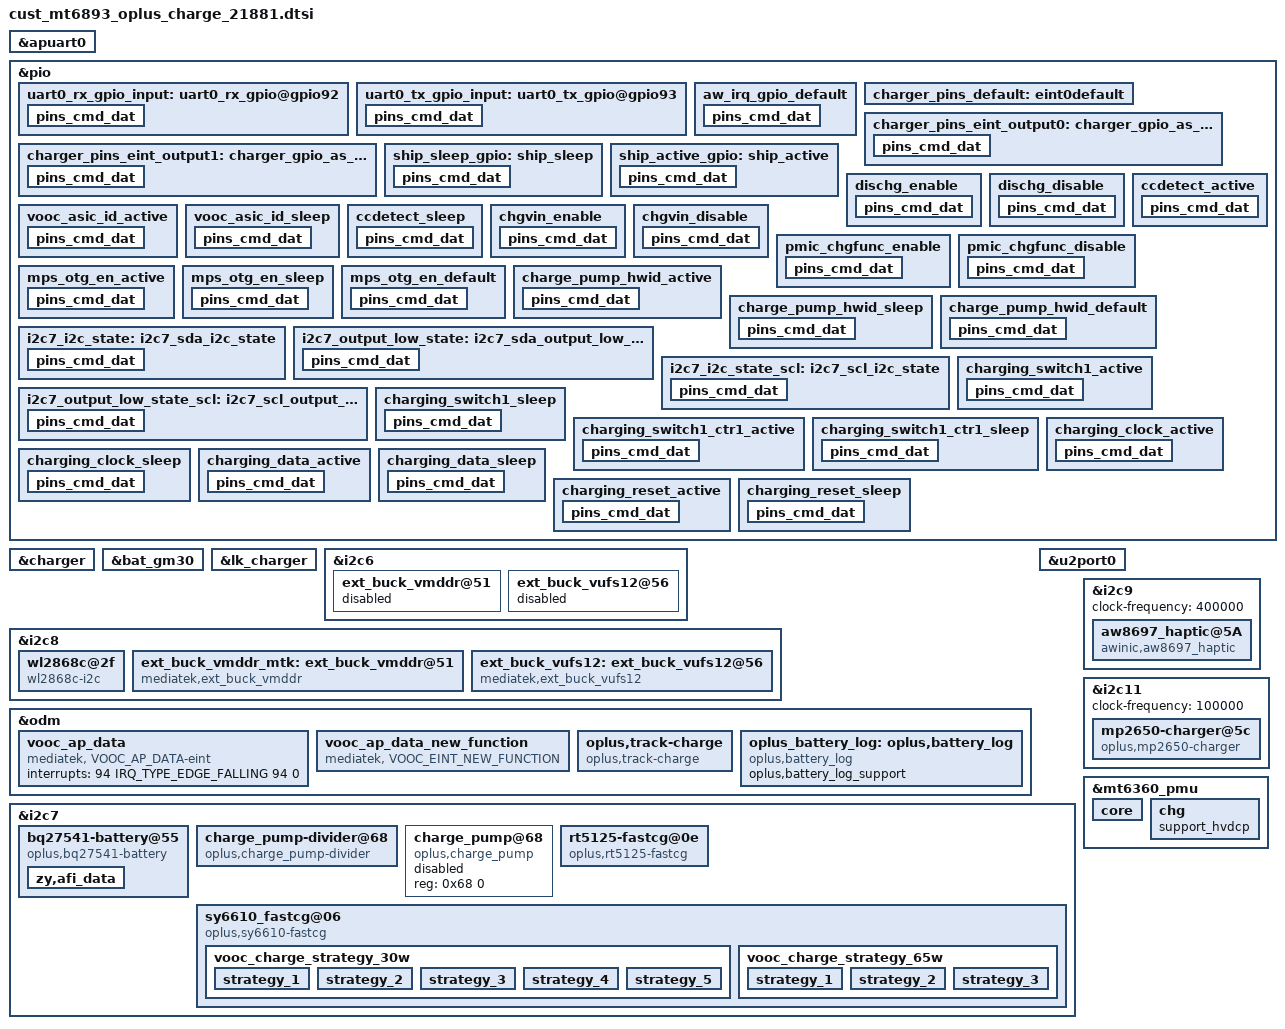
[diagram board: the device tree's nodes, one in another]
// SPDX-License-Identifier: GPL-2.0-only
/*
* Copyright (C) 2021-2020 Oplus. All rights reserved.
*/

/* charge start */
&apuart0 {
	pinctrl-names = "uart0_rx_gpio", "uart0_tx_gpio";
	pinctrl-0 = <&uart0_rx_gpio_input>;
	pinctrl-1 = <&uart0_tx_gpio_input>;
	status = "okay";
};

&pio {
	uart0_rx_gpio_input:uart0_rx_gpio@gpio92 {
		pins_cmd_dat {
			pinmux = <PINMUX_GPIO92__FUNC_GPIO92>;
			input-enable;
			slew-rate = <0>;
			bias-disable;
		};
	};

	uart0_tx_gpio_input:uart0_tx_gpio@gpio93 {
		pins_cmd_dat {
			pinmux = <PINMUX_GPIO93__FUNC_GPIO93>;
			input-enable;
			slew-rate = <0>;
			bias-disable;
		};
	};
};
&charger {
	io-channels =  <&auxadc 4>,
		<&auxadc 5>;
	io-channel-names = "auxadc4-usb_temp_v_l",
	"auxadc5-usb_temp_v_r";

	pinctrl-names = "default", "charger_gpio_as_output_low", "charger_gpio_as_output_high", "ship_sleep", "ship_active",
		"dischg_enable", "dischg_disable", "chgvin_enable", "chgvin_disable", "pmic_chgfunc_enable", "pmic_chgfunc_disable",
		"ccdetect_active","ccdetect_sleep";
	pinctrl-0 = <&charger_pins_default>;
	pinctrl-1 = <&charger_pins_eint_output0>;	//USB_ON -> USB_SWITCH:(UART && USB)
	pinctrl-2 = <&charger_pins_eint_output1>;
	pinctrl-3 = <&ship_sleep_gpio>;				//ship_mode
	pinctrl-4 = <&ship_active_gpio>;
	pinctrl-5 = <&dischg_enable>;				//usb_hightemp_port
	pinctrl-6 = <&dischg_disable>;
	pinctrl-7 = <&chgvin_enable>;					//EVB GPIO30 chgvin
	pinctrl-8 = <&chgvin_disable>;
	pinctrl-9 = <&pmic_chgfunc_enable>;				//EVB GPIO26 chg_enable
	pinctrl-10 = <&pmic_chgfunc_disable>;
	//pinctrl-5 = <&shortc_active_gpio>;
	pinctrl-11 = <&ccdetect_active>;
	pinctrl-12 = <&ccdetect_sleep>;
	qcom,hv_flashled_support;
	qcom,smart_charging_screenoff;
	qcom,usbtemp_batttemp_gap = <18>;

	qcom,usbtemp_cool_down_temp_gap= <12>;
	qcom,usbtemp_cool_down_recovery_temp_gap = <6>;

	qcom,usbtemp_cool_down_temp_first_gap = <12>;
	qcom,usbtemp_cool_down_recovery_temp_first_gap= <6>;

	qcom,usbtemp_cool_down_temp_second_gap = <17>;
	qcom,usbtemp_cool_down_recovery_temp_second_gap = <11>;
	qcom,new_usbtemp_cool_down_support;

	qcom,input_current_charger_ma = <2000>;
	qcom,input_current_usb_ma = <500>;
	qcom,input_current_cdp_ma = <1500>;
	qcom,input_current_led_ma = <1200>;
	qcom,input_current_led_ma_high = <1200>;
	qcom,input_current_led_ma_warm = <1500>;
	qcom,input_current_led_ma_normal = <2000>;
	qcom,input_current_led_ma_forcmcc = <500>;
	qcom,input_current_camera_ma = <1200>;
	qcom,input_current_calling_ma = <1500>;
	qcom,qc_input_current_charger_ma = <2000>;
	qcom,pd_input_current_charger_ma = <2000>;

	qcom,iterm_disabled = <0>;
	qcom,iterm_ma = <250>;
	qcom,recharge-mv = <100>;

	qcom,batt_capacity_mah = <4500>; /*typical capacity*/

	qcom,removed_bat_decidegc = <190>;  /* < -19C */

	qcom,cold_bat_decidegc = <100>;  /*-10C~0C*/
	qcom,temp_cold_vfloat_mv = <4438>;
	qcom,temp_cold_fastchg_current_ma = <562>;

	qcom,little_cold_bat_decidegc = <0>;    /* 0C ~ 5C */
	qcom,temp_little_cold_vfloat_mv = <4438>;
	qcom,temp_little_cold_fastchg_current_ma_high = <1100>;
	qcom,temp_little_cold_fastchg_current_ma_low = <1100>;
	qcom,temp_little_cold_fastchg_current_ma = <1100>;
	qcom,qc_temp_little_cold_fastchg_current_ma_high = <2000>;
	qcom,qc_temp_little_cold_fastchg_current_ma_low = <1462>;
	qcom,pd_temp_little_cold_fastchg_current_ma_high = <2000>;
	qcom,pd_temp_little_cold_fastchg_current_ma_low = <1462>;

	qcom,cool_bat_decidegc = <50>;  /* 5C ~ 12C */
	qcom,temp_cool_vfloat_mv = <4438>;
	qcom,temp_cool_fastchg_current_ma_high = <1100>;
	qcom,temp_cool_fastchg_current_ma_low = <1100>;
	qcom,qc_temp_cool_fastchg_current_ma_high = <2000>;
	qcom,qc_temp_cool_fastchg_current_ma_low = <2000>;
	qcom,pd_temp_cool_fastchg_current_ma_high = <2000>;
	qcom,pd_temp_cool_fastchg_current_ma_low = <2000>;

	qcom,little_cool_bat_decidegc = <120>;  /* 12C ~ 16C */
	qcom,temp_little_cool_vfloat_mv = <4438>;
	qcom,temp_little_cool_fastchg_current_ma = <1100>;
	qcom,pd_temp_little_cool_fastchg_current_ma = <2000>;
	qcom,qc_temp_little_cool_fastchg_current_ma = <2000>;

	qcom,normal_bat_decidegc = <160>;       /* 16C ~ 45C */
	qcom,temp_normal_vfloat_mv = <4438>;
	qcom,temp_normal_fastchg_current_ma = <1100>;
	qcom,pd_temp_normal_fastchg_current_ma = <2000>;
	qcom,qc_temp_normal_fastchg_current_ma = <2000>;

	qcom,warm_bat_decidegc = <450>;         /* 45C ~ 53C */ /*8pin Bat Vooc project need add 3 degree C*/
	qcom,temp_warm_vfloat_mv = <4130>;
	qcom,temp_warm_fastchg_current_ma = <1100>;
	qcom,pd_temp_warm_fastchg_current_ma = <1237>;
	qcom,qc_temp_warm_fastchg_current_ma = <1237>;
	qcom,temp_warm_fastchg_current_ma_led_on = <500>;

	qcom,hot_bat_decidegc = <530>;  /* > 53C */

	qcom,non_standard_vfloat_mv = <3980>;
	qcom,non_standard_fastchg_current_ma = <512>;

	qcom,short_c_bat_cv_mv = <4330>;
	qcom,short_c_bat_vfloat_mv = <3800>;
	qcom,short_c_bat_fastchg_current_ma = <512>;
	qcom,short_c_bat_vfloat_sw_limit = <3750>;

	qcom,cold_vfloat_sw_limit = <4385>;
	qcom,little_cold_vfloat_sw_limit = <4385>;
	qcom,cool_vfloat_sw_limit = <4385>;
	qcom,little_cool_vfloat_sw_limit = <4385>;
	qcom,normal_vfloat_sw_limit = <4385>;
	qcom,warm_vfloat_sw_limit = <4080>;
	qcom,non_standard_vfloat_sw_limit = <3930>;

	qcom,max_chg_time_sec = <63360>;
	qcom,charger_hv_thr = <9900>;
	qcom,charger_recv_thr = <9500>;
	qcom,charger_lv_thr = <3400>;
	qcom,vbatt_full_thr = <4438>;
	qcom,vbatt_hv_thr = <4600>;

	qcom,vfloat_step_mv = <8>;
	qcom,non_standard_vfloat_over_sw_limit = <3990>;
	qcom,cold_vfloat_over_sw_limit = <4445>;
	qcom,little_cold_vfloat_over_sw_limit = <4445>;
	qcom,cool_vfloat_over_sw_limit = <4445>;
	qcom,little_cool_vfloat_over_sw_limit = <4445>;
	qcom,normal_vfloat_over_sw_limit = <4445>;
	qcom,warm_vfloat_over_sw_limit = <4140>;

	qcom,vbatt_power_off = <3300>;
	qcom,vbatt_soc_1 = <3310>;
	qcom,vooc_project = <7>;
	qcom,chg_ctrl_by_vooc;
	qcom,vbatt_num = <2>;
	//qcom,internal_gauge_with_asic = <1>;
	qcom,ffc_support;
	qcom,new_ui_warning_support;
	qcom,dual_ffc;
	//recharge_after_full;
	qcom,chargerid_support;

	qcom,normal_vterm_hw_inc = <18>;
	qcom,non_normal_vterm_hw_inc = <18>;

	qcom,ff1_normal_fastchg_ma = <550>;
	qcom,ff1_warm_fastchg_ma = <550>;

	qcom,ffc2_normal_fastchg_ma = <350>;/*12C~35c*/
	qcom,ffc2_temp_warm_decidegc = <350>;
	qcom,ffc2_warm_fastchg_ma = <350>;/*35C~40c*/
	qcom,ffc2_temp_high_decidegc = <400>;
	qcom,ffc2_temp_low_decidegc = <120>;

	qcom,ff1_exit_step_ma = <150>;
	qcom,ff1_warm_exit_step_ma = <150>;
	qcom,ffc2_exit_step_ma = <150>;
	qcom,ffc2_warm_exit_step_ma = <150>;

	qcom,ffc_normal_vfloat_sw_limit = <4445>;
	qcom,ffc_temp_normal_vfloat_mv = <4500>;
	qcom,ffc_normal_vfloat_over_sw_limit = <4500>;
	qcom,ffc_warm_vfloat_sw_limit = <4445>;
	qcom,ffc_temp_warm_vfloat_mv = <4500>;
	qcom,ffc_warm_vfloat_over_sw_limit = <4500>;

	qcom,ffc2_normal_vfloat_sw_limit = <4440>;
	qcom,ffc2_temp_normal_vfloat_mv = <4500>;
	qcom,ffc2_normal_vfloat_over_sw_limit = <4500>;
	qcom,ffc2_warm_vfloat_sw_limit = <4440>;
	qcom,ffc2_temp_warm_vfloat_mv = <4500>;
	qcom,ffc2_warm_vfloat_over_sw_limit = <4500>;

	qcom,overchg_normal_fastchg_ma = <700>;/*16C~35c*/
	qcom,overchg_temp_warm_decidegc = <350>;
	qcom,overchg_warm_fastchg_ma = <750>;/*35C~40c*/
	qcom,overchg_temp_high_decidegc = <400>;

	qcom,overchg_normal_vfloat_sw_limit = <4450>;
	qcom,overchg_temp_normal_vfloat_mv = <4500>;
	qcom,overchg_normal_vfloat_over_sw_limit = <4500>;

	qcom,default_iterm_ma = <250>;
	qcom,default_temp_normal_fastchg_current_ma = <1100>;
	qcom,default_normal_vfloat_sw_limit = <4385>;
	qcom,default_temp_normal_vfloat_mv = <4438>;
	qcom,default_normal_vfloat_over_sw_limit = <4445>;

	qcom,default_temp_little_cool_fastchg_current_ma = <1100>;
	qcom,default_little_cool_vfloat_sw_limit = <4385>;
	qcom,default_temp_little_cool_vfloat_mv = <4438>;
	qcom,default_little_cool_vfloat_over_sw_limit = <4445>;

	qcom,input_current_vooc_led_ma_high = <1200>;
	qcom,input_current_vooc_led_ma_warm = <1800>;
	qcom,input_current_vooc_led_ma_normal = <3600>;
	qcom,input_current_vooc_ma_normal = <3600>;
	qcom,vooc_temp_bat_normal_decidegc = <350>;
	qcom,input_current_vooc_ma_warm = <3200>;
	qcom,vooc_temp_bat_warm_decidegc = <370>;
	qcom,input_current_vooc_ma_high = <2200>;
	qcom,vooc_temp_bat_hot_decidegc = <440>;

	qcom,charger_current_vooc_ma_normal = <1800>;

	//for PD9V or QC9V
	qcom,vbatt_pdqc_to_5v_thr = <4100>;
	qcom,vbatt_pdqc_to_9v_thr = <4000>;

	oplus,aging_ffc_version = <1>;

	//for control:
	//qcom,suspend_after_full;
	qcom,check_batt_full_by_sw;
	qcom,external_gauge;
	qcom,chg_ctrl_by_calling;
	qcom,chg_ctrl_by_lcd;
	qcom,chg_ctrl_by_camera;
	qcom,sw_vfloat_over_protect_enable;
	qcom,support_abnormal_adapter;
	qcom,support_ntc_01c_precision;
	qcom,vooc_show_ui_soc_decimal;
	qcom,ui_soc_decimal_speedmin = <20>;//2A

	//GPIO config:
	qcom,chargerid_switch-gpio = <&pio 192 0x00>;
	qcom,ship-gpio = <&pio 27 0x00>;               //check
	qcom,dischg-gpio = <&pio 51 0x00>;//VBUS_SHORT
	//qcom,shortc-gpio = <&pio 121 0x00>;
	qcom,ccdetect-gpio = <&pio 5 0x00>;//USB_ACC_INT
	qcom,supported_hiz_gnd_cable;
	//Lukaili Add for camera flash led
	qcom,chgvin = <&pio 30 0x00>;            //check
	qcom,pmic_chgfunc = <&pio 26 0x00>;             //check

};

&bat_gm30 {
	FUELGAGUE_APPLY = <(0)>;
	DISABLE_MTKBATTERY = <(1)>;
};

&lk_charger {
	charger_by_buckboost;
	support_tuv_authentication;
	max_charger_voltage = <9900000>;

	support_sdp_screenoff;
	support_new_charger_stander;
	usb_charger_current = <500000>;
	ac_charger_input_current = <2000000>;
	non_std_ac_charger_current = <2000000>;
	charging_host_charger_current = <1500000>;
	precharge_1_step_current = <350>;

	cold_bat_decidegc = <10>;  /*-10C~0C*/
	dcp_temp_cold_fastchg_current = <300>;
	usb_temp_cold_fastchg_current = <300>;
	cdp_temp_cold_fastchg_current = <300>;

	little_cold_bat_decidegc = <0>;    /*0C~5C*/
	dcp_temp_little_cold_fastchg_current = <500>;
	usb_temp_little_cold_fastchg_current = <300>;
	cdp_temp_little_cold_fastchg_current = <500>;

	cool_bat_decidegc = <5>;  /*5C~12C*/
	dcp_temp_cool_fastchg_current = <800>;
	usb_temp_cool_fastchg_current = <300>;
	cdp_temp_cool_fastchg_current = <800>;

	little_cool_bat_decidegc = <12>;  /*12C~16C*/
	dcp_temp_little_cool_fastchg_current = <1100>;
	usb_temp_little_cool_fastchg_current = <300>;
	cdp_temp_little_cool_fastchg_current = <800>;

	normal_bat_decidegc = <16>;       /*16C~45C*/
	dcp_temp_normal_fastchg_current = <1100>;
	usb_temp_normal_fastchg_current = <300>;
	cdp_temp_normal_fastchg_current = <800>;

	warm_bat_decidegc = <45>;    /*45C~53C*/
	dcp_temp_warm_fastchg_current = <1100>;
	usb_temp_warm_fastchg_current = <300>;
	cdp_temp_warm_fastchg_current = <800>;

	hot_bat_decidegc = <53>;
};

/delete-node/ &ext_buck_vmddr_mtk;

&i2c6 {
	ext_buck_vmddr@51 {
		status = "disabled";
	};

	ext_buck_vufs12@56 {
		status = "disabled";
	};
};

&i2c8 {
        wl2868c@2f {
                compatible = "wl2868c-i2c";
                reg = <0x2f>;
                id_reg = <0x00>;
                id_val = <0x82>;
                vin1_vol = <800000>;
                vin2_vol = <1504000>;
                en-gpios = <&pio 29 1>;
        };
		ext_buck_vmddr_mtk:ext_buck_vmddr@51 {
			compatible = "mediatek,ext_buck_vmddr";
			reg = <0x51>;
			regulator-name = "ext_buck_vmddr";
			regulator-min-microvolt = <300000>;
			regulator-max-microvolt = <1300000>;
			status = "okay";
		};

		ext_buck_vufs12: ext_buck_vufs12@56 {
			compatible = "mediatek,ext_buck_vufs12";
			reg = <0x56>;
			regulator-name = "ext_buck_vufs12";
			regulator-min-microvolt = <300000>;
			regulator-max-microvolt = <1300000>;
			regulator-always-on;
			status = "okay";
		};
};

&odm {
	vooc_ap_data:vooc_ap_data {
		compatible = "mediatek, VOOC_AP_DATA-eint";
		interrupts = <94 IRQ_TYPE_EDGE_FALLING 94 0>;
	};
	vooc_ap_data_new_function:vooc_ap_data_new_function {
		compatible = "mediatek, VOOC_EINT_NEW_FUNCTION";
	};

	oplus,track-charge {
		compatible = "oplus,track-charge";
		track,fast_chg_break_t_thd = <1000>;
		track,general_chg_break_t_thd = <200>;
		track,voocphy_type = <4>;
		track,wired_max_power = <80000>;
		track,wired_fast_chg_scheme = <1>;
	};

	oplus_battery_log: oplus,battery_log {
		compatible = "oplus,battery_log";
		oplus,battery_log_support;
	};
};

&u2port0 {
	mediatek,eye-vrt = <7>; /* 0~7 */
	mediatek,eye-term = <7>; /* 0~7 */
	mediatek,eye-rev6 = <3>; /* 0~3 */
	mediatek,eye-disc = <0xF>; /* 0~8 */
	mediatek,host-eye-vrt = <7>; /* 0~7 */
	mediatek,host-eye-term = <7>; /* 0~7 */
	mediatek,host-eye-rev6 = <3>; /* 0~3 */
	mediatek,host-eye-disc = <0xB>; /* 0~8 */
};

&i2c7 {
	status = "okay";
	clock-frequency = <100000>;

	bq27541-battery@55 {
		status = "okay";
		compatible = "oplus,bq27541-battery";
		reg = <0x55 0>;
		qcom,modify-soc-smooth;
		qcom,modify-soc-calibration;
		qcom,batt_bq28z610;
		qcom,sha1_key_index = <1>;
		//qcom,bq28z610_need_balancing;
		zy,afi_data{
			battery,name = "BLP861";
			qmax_min = <1776>;
			qmax_max = <2553>;
			static_df_checksum_3e = [25 E4];			//len 2
			static_df_checksum_60 = [3A 06];			//len 2
			afi_buf_num = <7>;
			afi_buf_0 = [	//diffrent from BLP863
				11 D0 11 17 11 D0 11 17 11 D0 11 17 11 D0 11 17
				01 0A 8C 0A 0C 1C 21 34 02 FF CE 02 EC 78 02 FF
				CE 05 C2 0A C2 0A 72 A3 0A 0C D1 02 0C 9F 0D 03
				02 0C D1 0A 79 02 0A AB 09 E3 02 0A 15 07 D0 07
				08 07 08 00 02 09 C4 07 D0 D2 F0 00 02 03 E8 05
				11 EE 05 0E 74 00 0A 01 F4 0A 07 08 0E 74 00 0A
				01 F4 0A 00 0A 05 FF F6 05 0A 0A AB 0B 23 0B 73
				0B A5 0B D7 0C D1 00 0A 00 58 00 2C 11 5D 00 84
				01 60 01 08 11 5D 07 BC 0F A4 0B B0 11 5D 09 CC
				11 88 0D C0 11 5D 03 F4 07 BC 05 D8 09 C4 0D 48
				0E D8 0F A0 00 01 01 2C 01 2C 01 2C 01 2C 00 4B
				03 84 28 01 65 01 6B 03 00 00 46 50 50 00 30 00
				96 00 AF 08 AC 06 B6 1E 3C 5A
				];
			afi_buf_1 = [
				64 63 64 61 00 01 01 02 05 21 1C 00 A2 40 05 57
				20 00 00 03 00 00 0A F0 0A 28 14 0A 14 10 E0 64
				07 D0 00 03 0F 00 14 04 19 C8 00
				];
			afi_buf_2 = [	//diffrent from BLP863
				AA 21 10 03 03 05 41 07 00 09 C3 0B CB 0D 07 0F
				B8 11 5A 13 BC 15 DE 17 D1 19 D7 1B A9 5D 28 B5
				00 33 22 A4 24 82 26 6F 28 C0 2A 03 2C 44 2E E7
				30 79 32 9B 34 3C 36 DE 38 D5 3A 88 7C 4D 08 C2
				08 C6 33
				];
			afi_buf_3 = [
				11 38 11 38 01 2C FF 38 FE 20 FE D5 FC 18 00 6A
				00 32 00 32
				];
			afi_buf_4 = [25 E4];	//diffrent from BLP863
			afi_buf_5 = [			//diffrent from BLP863
				FF 21 10 03 03 05 41 07 00 09 C3 0B CB 0D 07 0F
				B8 11 5A 13 BC 15 DE 17 D1 19 D7 1B A9 5D 28 E0
				00 33 22 A4 24 82 26 6F 28 C0 2A 03 2C 44 2E E7
				30 79 32 9B 34 3C 36 DE 38 D5 3A 6A 7C FB 01 01
				00 00 00 00 00 14 00 0F 00 46 00 3C 00 3C 01 3C
				FF F6 FE 0C 32
				];
			afi_buf_6 = [			//diffrent from BLP863
				E4 E3 20 28 26 A2 24 43 2A E9 08 96 0E 94 0C BA
				12 C0 10 FE 16 DC 14 11 1A 5B FB C5 FD 66 FF 27
				C1 F5 C3 72 C5 0B C7 AD C9 4F CB 4F CD 6F CF 8F
				F1 2E F3 EE F5 A9 F7 AC F9 43 FB E2 FD 24 FF A8
				81 77 83 B0 85 17 87 E8 89 87 8B 85 8D 41 EF 56
				31 8F CD CE CB 8F C9 B1 C7 D0 C5 F9 C3 93 C1 25
				FF 8D FD 72 DB AB D9 14 D7 52 D5 96 B3 CF B1 2F
				8F BE 8D 68 AB 52 A9 88 78 4F 7A 94 5C 7F 5E FF
				A0 22 82 58 84 74 86 0B 88 0F 15 34 D3 C5 B1 7D
				8F 00 CD 5B AB 20 A9 29 E7 80 C5 8E 62 18 43 E2
				9E 61 5D F0 5B 76 59 13 57 DB 55 A0 53 98 51 9A
				4F 27 4D C4 4B 22 49 42 47 E1 45 01 BC EF BE FF
				1F 99 1D 5A 1B 1E 19 5B 37 EF 15 35 33 8C 11 F5
				0F E9 0D E4 0B 62 09 E2 07 0D 05 E0 23 03 FE 5A
				E0 E1 E2 20 E4 26 E6 FE C8 6C 8A EB AC AC ED EB
				90 10 B3 F3 78 F5 B6 D4 E1 38 66 3A 17 DD EC FF
				8C 21 62 A3 A4 A1 CE 07 8A 05 4B 28 09 81 4E 04
				10 51 12 13 75 02 36 92 5E 5F 5B 5B 7C 5D 5F 5E
				61 67 E3 83 A4 CA 86 A5 28 30 6A BC EC 2D 2E AD
				54 31 2B 73 E9 16 BA 76 58 69 DC FB 93 3D 3E DE
				B0 41 A3 A3 3C 45 46 47 48 49 A7 2A 05 4D E2 6E
				19 51 B7 73 7D 55 B7 57 70 59 BF BA 14 5D 5E 5F
				60 61 62 63 64 65 C3 86 21 69 4B AA A4 6D 6E 6F
				70 71 72 73 74 75 76 77 78 79 7A 7B 7C 7D 7E 7F
				80 7E 02 83 E4 C5 C6 87 C8 89 8A 8B 8C 8D 4F 8D
				90 9E FC 99 D4 74 B6 85 98 80 9A 82 1C 9D 5D FF
				A0 2D A2 FC 04 29 A6 BE C8 89 61 AB F3 2F 8E BD
				15 3D 12 F8 14 B5 B6 B7 0C B2 0C E4 0A 5F 01 2C
				];
		};
	};

	charge_pump-divider@68 {
		status = "okay";
		compatible = "oplus,charge_pump-divider";
		reg = <0x68 0>;
		oplus,charge_pump-hwid-gpio = <&pio 147 0>;
		pinctrl-names = "charge_pump_hwid_active", "charge_pump_hwid_sleep", "charge_pump_hwid_default";
		pinctrl-0 = <&charge_pump_hwid_active>;
		pinctrl-1 = <&charge_pump_hwid_sleep>;
		pinctrl-2 = <&charge_pump_hwid_default>;
	};

	charge_pump@68 {
		status = "disabled";
		compatible = "oplus,charge_pump";
		reg = <0x68 0>;
	};

	rt5125-fastcg@0e{
		status = "okay";
		compatible = "oplus,rt5125-fastcg";
		reg = <0x0e>;
		qcom,vooc_reply_mcu_bits = <7>;
		qcom,vooc-version = <5>;
		qcom,vooc-low-temp = <0>;
		qcom,oplus_batt_4250mv;
		qcom,vooc-high-soc = <90>;
		qcom,vooc-high-temp = <500>;
		qcom,vooc-low-soc = <1>;
		//qcom,vooc_fw_update_newmethod;
		qcom,vooc-fw-type = <5>;
		qcom,support_vooc_by_normal_charger_path;
		qcom,support_high_watt_svooc;

		qcom,vooc-little-cold-temp = <50>;
		qcom,vooc-cool-temp = <120>;
		qcom,vooc-little-cool-temp = <200>;
		qcom,vooc-normal-low-temp = <350>;
		qcom,vooc-normal-high-temp = <440>;

		qcom,vooc-warm-allow-vol = <4130>;
		qcom,vooc-warm-allow-soc = <50>;
		qcom,vooc-little-cool-to-normal-temp = <180>;
		qcom,vooc-normal-to-little-cool-current = <0x05>;//5A

		qcom,vooc_cool_bat_volt = <3650>;
		qcom,vooc_little_cool_bat_volt = <3550>;
		qcom,vooc_normal_bat_volt = <3450>;
		qcom,vooc_warm_bat_volt = <3350>;

		qcom,vooc_cool_bat_suspend_volt = <3650>;
		qcom,vooc_little_cool_bat_suspend_volt = <3550>;
		qcom,vooc_normal_bat_suspend_volt = <3450>;
		qcom,vooc_warm_bat_suspend_volt = <3350>;

		qcom,vooc_multistep_adjust_current_support;
		qcom,vooc_multistep_initial_batt_temp = <1000>;
		qcom,vooc_strategy_normal_current = <0x0f>;

		qcom,vooc_batt_over_high_temp = <510>;
		qcom,vooc_batt_over_low_temp = <45>;
		qcom,vooc_over_high_or_low_current = <0x0>;

		qcom,vooc_strategy1_batt_high_temp0 = <400>;
		qcom,vooc_strategy1_batt_high_temp1 = <420>;
		qcom,vooc_strategy1_batt_high_temp2 = <430>;
		qcom,vooc_strategy1_batt_low_temp2 = <420>;
		qcom,vooc_strategy1_batt_low_temp1 = <410>;
		qcom,vooc_strategy1_batt_low_temp0 = <390>;

		qcom,vooc_strategy1_high_current0 = <0x09>;  // 5A
		qcom,vooc_strategy1_high_current1 = <0x07>;  // 4A
		qcom,vooc_strategy1_high_current2 = <0x05>;  // 3A
		qcom,vooc_strategy1_low_current2 = <0x07>;   // 4A
		qcom,vooc_strategy1_low_current1 = <0x09>;   // 5A
		qcom,vooc_strategy1_low_current0 = <0x0f>;

		qcom,vooc_strategy2_batt_up_temp1 = <375>;
		qcom,vooc_strategy2_batt_up_down_temp2 = <380>;
		qcom,vooc_strategy2_batt_up_temp3 = <390>;
		qcom,vooc_strategy2_batt_up_down_temp4 = <400>;
		qcom,vooc_strategy2_batt_up_temp5 = <410>;
		qcom,vooc_strategy2_batt_up_temp6 = <415>;
		qcom,vooc_strategy2_high0_current = <0x09>;
		qcom,vooc_strategy2_high1_current = <0x07>;
		qcom,vooc_strategy2_high2_current = <0x05>;
		qcom,vooc_strategy2_high3_current = <0x03>;
		qcom,abnormal_adapter_current = <0x00 0x00 0x09 0x09 0x07 0x07 0x05 0x05 0x03 0x03>;
		qcom,vooc_current_lvl = <1000
									1500
									2000
									2500
									3000
									3500
									4000
									4500
									5000
									5500
									6000
									6500
									7000
									7500
									8000
									8500
									9000
									9500
									10000
									10500
									11000
									11500
									12000
									12500>;
		pinctrl-names = "switch1_act_switch2_act", "switch1_sleep_switch2_sleep",
						"switch1_act_switch3_act", "switch1_sleep_switch3_sleep",
						"switch1_act_switch2_sleep", "switch1_sleep_switch2_act",
						"clock_active","clock_sleep",
						"data_active","data_sleep",
						"reset_active","reset_sleep",
						"vooc_asic_id_active","vooc_asic_id_sleep";
		pinctrl-0 = <&charging_switch1_active>;
		pinctrl-1 = <&charging_switch1_sleep>;
		pinctrl-2 = <&charging_switch1_active>;
		pinctrl-3 = <&charging_switch1_sleep>;
		pinctrl-4 = <&charging_switch1_active>;
		pinctrl-5 = <&charging_switch1_sleep>;
		pinctrl-6 = <&charging_clock_active>;
		pinctrl-7 = <&charging_clock_sleep>;
		pinctrl-8 = <&charging_data_active>;
		pinctrl-9 = <&charging_data_sleep>;
		pinctrl-10 = <&charging_reset_active>;
		pinctrl-11 = <&charging_reset_sleep>;
		pinctrl-12 = <&vooc_asic_id_active>;
		pinctrl-13 = <&vooc_asic_id_sleep>;

		qcom,charging_switch1-gpio 		= <&pio 191 0x00>;            //SW_CTRL
		//qcom,charging_switch1_ctr1-gpio 	= <&pio 148 0x00>;

		qcom,charging_reset-gpio 			= <&pio 189 0x00>;//MCU_EN
		qcom,charging_clock-gpio 			= <&pio 95 0x00>;//AP_CLK
		qcom,charging_data-gpio 			= <&pio 94 0x00>;//AP_DATA
		qcom,vooc_asic_id-gpio				= <&pio 187 0x00>;
		qcom,supported_hiz_gnd_cable;
		qcom,parse_fw_from_dt;
		vooc,firmware_data = [
			e8 05 00 20 31 01 00 00 39 01 00 00 3b 01 00 00
			00 00 00 00 00 00 00 00 00 00 00 00 00 00 00 00
			00 00 00 00 00 00 00 00 00 00 00 00 3d 01 00 00
			00 00 00 00 00 00 00 00 3f 01 00 00 41 01 00 00
			a1 04 00 00 d5 09 00 00 c9 07 00 00 43 01 00 00
			b5 09 00 00 0d 04 00 00 69 08 00 00 7d 08 00 00
			a1 09 00 00 dd 07 00 00 f1 07 00 00 2d 03 00 00
			25 06 00 00 39 06 00 00 4d 06 00 00 43 01 00 00
			6d 06 00 00 43 01 00 00 05 08 00 00 00 f0 02 f8
			00 f0 3e f8 0c a0 30 c8 08 38 24 18 2d 18 a2 46
			67 1e ab 46 54 46 5d 46 ac 42 01 d1 00 f0 30 f8
			7e 46 0f 3e 0f cc b6 46 01 26 33 42 00 d0 fb 1a
			a2 46 ab 46 33 43 18 47 50 2c 00 00 70 2c 00 00
			10 3a 02 d3 78 c8 78 c1 fa d8 52 07 01 d3 30 c8
			30 c1 01 d5 04 68 0c 60 70 47 00 00 00 23 00 24
			00 25 00 26 10 3a 01 d3 78 c1 fb d8 52 07 00 d3
			30 c1 00 d5 0b 60 70 47 1f b5 1f bd 10 b5 10 bd
			00 f0 d8 f8 11 46 ff f7 f7 ff 01 f0 cd ff 00 f0
			f0 f8 03 b4 ff f7 f2 ff 03 bc 00 f0 f7 f8 00 00
			07 48 80 47 07 48 00 47 fe e7 fe e7 fe e7 fe e7
			fe e7 fe e7 04 48 05 49 03 4a 05 4b 70 47 00 00
			65 08 00 00 8d 00 00 00 e8 01 00 20 e8 05 00 20
			e8 01 00 20 00 22 03 09 8b 42 2c d3 03 0a 8b 42
			11 d3 00 23 9c 46 4e e0 03 46 0b 43 3c d4 00 22
			43 08 8b 42 31 d3 03 09 8b 42 1c d3 03 0a 8b 42
			01 d3 94 46 3f e0 c3 09 8b 42 01 d3 cb 01 c0 1a
			52 41 83 09 8b 42 01 d3 8b 01 c0 1a 52 41 43 09
			8b 42 01 d3 4b 01 c0 1a 52 41 03 09 8b 42 01 d3
			0b 01 c0 1a 52 41 c3 08 8b 42 01 d3 cb 00 c0 1a
			52 41 83 08 8b 42 01 d3 8b 00 c0 1a 52 41 43 08
			8b 42 01 d3 4b 00 c0 1a 52 41 41 1a 00 d2 01 46
			52 41 10 46 70 47 5d e0 ca 0f 00 d0 49 42 03 10
			00 d3 40 42 53 40 00 22 9c 46 03 09 8b 42 2d d3
			03 0a 8b 42 12 d3 fc 22 89 01 12 ba 03 0a 8b 42
			0c d3 89 01 92 11 8b 42 08 d3 89 01 92 11 8b 42
			04 d3 89 01 3a d0 92 11 00 e0 89 09 c3 09 8b 42
			01 d3 cb 01 c0 1a 52 41 83 09 8b 42 01 d3 8b 01
			c0 1a 52 41 43 09 8b 42 01 d3 4b 01 c0 1a 52 41
			03 09 8b 42 01 d3 0b 01 c0 1a 52 41 c3 08 8b 42
			01 d3 cb 00 c0 1a 52 41 83 08 8b 42 01 d3 8b 00
			c0 1a 52 41 d9 d2 43 08 8b 42 01 d3 4b 00 c0 1a
			52 41 41 1a 00 d2 01 46 63 46 52 41 5b 10 10 46
			01 d3 40 42 00 2b 00 d5 49 42 70 47 63 46 5b 10
			00 d3 40 42 01 b5 00 20 c0 46 c0 46 02 bd 70 47
			70 47 70 47 75 46 00 f0 25 f8 ae 46 05 00 69 46
			53 46 c0 08 c0 00 85 46 18 b0 20 b5 ff f7 32 ff
			60 bc 00 27 49 08 b6 46 00 26 c0 c5 c0 c5 c0 c5
			c0 c5 c0 c5 c0 c5 c0 c5 c0 c5 40 3d 49 00 8d 46
			70 47 10 b5 04 46 c0 46 c0 46 20 46 ff f7 09 ff
			10 bd 00 00 00 48 70 47 88 01 00 20 01 49 18 20
			ab be fe e7 26 00 02 00 70 47 00 00 03 48 00 68
			01 21 09 03 88 43 01 49 08 60 70 47 00 70 00 40
			10 b5 01 20 15 49 c8 62 06 20 00 f0 b9 f8 4b 20
			c0 01 00 f0 b5 f8 4b 20 c0 01 00 f0 b1 f8 72 b6
			00 20 00 f0 59 fa 0d 48 40 68 01 28 01 d1 00 24
			00 e0 01 24 06 20 00 f0 a3 f8 00 20 07 49 88 62
			62 b6 06 20 00 f0 9c f8 4b 20 c0 01 00 f0 98 f8
			4b 20 c0 01 00 f0 94 f8 20 46 10 bd 00 03 0a 42
			00 b5 02 46 00 2a 03 d0 00 20 17 49 c8 62 02 e0
			01 20 15 49 c8 62 4b 20 c0 01 00 f0 81 f8 4b 20
			c0 01 00 f0 7d f8 72 b6 01 20 0f 49 88 62 06 20
			00 f0 76 f8 06 20 00 f0 73 f8 06 20 00 f0 70 f8
			00 20 09 49 88 62 62 b6 06 20 00 f0 69 f8 4b 20
			c0 01 00 f0 65 f8 4b 20 c0 01 00 f0 61 f8 01 20
			01 49 c8 62 00 bd 00 00 00 03 0a 42 06 48 c0 69
			c1 b2 06 48 c1 70 06 48 00 68 01 21 89 04 88 43
			03 49 08 60 70 47 00 00 00 30 00 40 81 01 00 20
			00 70 00 40 f0 b5 07 46 0d 46 14 46 00 26 00 f0
			a1 f8 aa 20 00 f0 ca f8 06 46 01 2e 00 d0 22 e0
			38 46 00 f0 c3 f8 06 46 01 2e 00 d0 1b e0 00 f0
			91 f8 ab 20 00 f0 ba f8 06 46 01 2e 00 d0 12 e0
			06 e0 01 20 00 f0 54 f8 20 70 64 1c 68 1e c5 b2
			01 2d f6 dc 00 20 00 f0 4b f8 20 70 64 1c 00 f0
			91 f8 01 20 f0 bd 00 f0 8d f8 00 20 fa e7 00 00
			05 49 09 68 01 22 d2 05 91 43 03 4a 11 60 03 49
			89 69 c8 b2 70 47 00 00 00 70 00 40 00 30 00 40
			00 e0 40 1e 00 28 fc d1 70 47 f0 b5 07 46 0c 46
			15 46 00 26 00 f0 56 f8 aa 20 00 f0 7f f8 06 46
			01 2e 00 d0 17 e0 38 46 00 f0 78 f8 06 46 01 2e
			00 d0 10 e0 09 e0 28 78 6d 1c 00 f0 6f f8 06 46
			01 2e 00 d0 07 e0 60 1e c4 b2 00 2c f3 d1 00 f0
			51 f8 01 20 f0 bd 00 f0 4d f8 00 20 fa e7 00 00
			1c b5 04 46 00 21 01 91 08 21 00 91 1e e0 68 46
			00 79 40 06 01 0e 01 91 72 b6 00 20 00 f0 6c f9
			06 20 ff f7 bd ff 0e 48 41 68 68 46 00 79 01 43
			c9 b2 01 91 00 20 0a 49 88 62 62 b6 04 20 ff f7
			af ff 68 46 00 78 40 1e c1 b2 00 91 68 46 00 78
			00 28 dc d1 20 46 ff f7 13 ff 68 46 00 79 1c bd
			00 03 0a 42 00 b5 01 20 00 f0 46 f9 00 20 00 f0
			43 f9 0c 20 ff f7 94 ff 72 b6 00 20 04 49 c8 62
			0c 20 ff f7 8d ff 00 20 01 49 88 62 62 b6 00 bd
			00 03 0a 42 00 b5 00 20 07 49 88 62 c8 62 06 20
			ff f7 7e ff 00 20 00 f0 27 f9 06 20 ff f7 78 ff
			01 20 00 f0 21 f9 00 bd 00 03 0a 42 30 b5 04 46
			08 25 15 e0 72 b6 e0 11 0d 49 c8 62 06 20 ff f7
			67 ff 00 20 00 f0 10 f9 06 20 ff f7 61 ff 00 bf
			60 06 04 0e 00 20 06 49 88 62 68 1e c5 b2 62 b6
			00 2d e7 d1 00 20 02 49 88 62 ff f7 91 fe 30 bd
			00 03 0a 42 03 48 00 68 01 21 c9 02 88 43 01 49
			08 60 70 47 00 70 00 40 03 48 00 68 01 21 89 02
			88 43 01 49 08 60 70 47 00 70 00 40 05 48 00 68
			01 21 49 02 88 43 03 49 08 60 01 20 02 49 08 70
			70 47 00 00 00 70 00 40 11 00 00 20 10 b5 10 48
			00 68 80 21 88 43 0e 49 08 60 0e 48 00 78 00 28
			0c d1 0d 48 00 68 40 08 40 00 40 1c 0a 49 08 60
			00 20 0a 49 08 70 01 20 06 49 08 70 08 48 00 78
			02 28 02 d1 00 f0 ae f9 01 e0 00 f0 71 fd 10 bd
			00 70 00 40 6d 00 00 20 00 10 00 40 38 00 00 20
			5f 00 00 20 c2 06 d2 0e 01 21 91 40 01 4a 11 60
			70 47 00 00 00 e1 00 e0 10 b5 00 28 19 da 1a 4a
			03 07 1b 0f 08 3b 9b 08 9b 00 d2 58 83 07 dc 0e
			ff 23 a3 40 9a 43 8b 07 1b 0e 84 07 e4 0e a3 40
			1a 43 11 4b 04 07 24 0f 08 3c a4 08 a4 00 1a 51
			18 e0 0e 4a 03 23 1b 02 d2 18 83 08 9b 00 d2 58
			83 07 dc 0e ff 23 a3 40 9a 43 8b 07 1b 0e 84 07
			e4 0e a3 40 1a 43 05 4b 03 24 24 02 1b 19 84 08
			a4 00 1a 51 10 bd 00 00 1c ed 00 e0 00 e1 00 e0
			10 b5 00 28 19 da 1a 4a 03 07 1b 0f 08 3b 9b 08
			9b 00 d2 58 83 07 dc 0e ff 23 a3 40 9a 43 8b 07
			1b 0e 84 07 e4 0e a3 40 1a 43 11 4b 04 07 24 0f
			08 3c a4 08 a4 00 1a 51 18 e0 0e 4a 03 23 1b 02
			d2 18 83 08 9b 00 d2 58 83 07 dc 0e ff 23 a3 40
			9a 43 8b 07 1b 0e 84 07 e4 0e a3 40 1a 43 05 4b
			03 24 24 02 1b 19 84 08 a4 00 1a 51 10 bd 00 00
			1c ed 00 e0 00 e1 00 e0 03 48 00 68 01 21 49 05
			88 43 01 49 08 60 70 47 00 70 00 40 03 48 00 68
			01 21 89 03 88 43 01 49 08 60 70 47 00 70 00 40
			03 48 00 68 01 21 49 03 88 43 01 49 08 60 70 47
			00 70 00 40 03 48 00 68 20 21 88 43 01 49 08 60
			70 47 00 00 00 70 00 40 01 46 00 20 00 29 0d d1
			07 e0 01 22 0d 4b 9a 62 40 1c 0d 4a 90 42 00 d9
			03 e0 0a 4a 12 68 00 2a f3 d0 0d e0 07 e0 01 22
			06 4b da 62 40 1c 06 4a 90 42 00 d9 03 e0 03 4a
			52 68 00 2a f3 d0 00 bf 70 47 00 00 00 03 0a 42
			50 c3 00 00 70 47 00 00 03 48 00 68 01 21 49 04
			88 43 01 49 08 60 70 47 00 70 00 40 10 b5 3b 48
			00 68 01 21 09 04 88 43 38 49 08 60 38 48 00 88
			00 28 05 d0 36 48 00 88 40 1e 35 49 08 80 15 e0
			7d 20 c0 00 32 49 08 80 32 48 00 88 00 28 04 d0
			30 48 00 88 40 1e 2f 49 08 80 2f 48 00 88 00 28
			04 d0 2d 48 00 88 40 1e 2b 49 08 80 2b 48 00 68
			00 28 04 d0 29 48 00 68 40 1e 28 49 08 60 28 48
			00 68 00 28 04 d0 26 48 00 68 40 1e 24 49 08 60
			24 48 00 68 00 28 04 d0 22 48 00 68 40 1e 21 49
			08 60 21 48 00 78 00 28 04 d0 1f 48 00 78 40 1e
			1d 49 08 70 1d 48 00 68 00 28 04 d0 1b 48 00 68
			40 1e 1a 49 08 60 1a 48 00 68 00 28 04 d0 18 48
			00 68 40 1e 16 49 08 60 16 48 00 78 40 1c 15 49
			08 70 08 46 00 78 c8 28 0e dd 00 20 08 70 12 48
			00 78 00 28 05 d0 00 20 01 f0 30 fb 01 20 0f 49
			08 70 01 20 0c 49 08 70 10 bd 00 00 00 70 00 40
			3a 00 00 20 3c 00 00 20 3e 00 00 20 40 00 00 20
			44 00 00 20 48 00 00 20 4c 00 00 20 50 00 00 20
			54 00 00 20 38 00 00 20 24 00 00 20 10 00 00 20
			03 48 00 68 01 21 c9 03 88 43 01 49 08 60 70 47
			00 70 00 40 0f 20 05 49 c8 60 05 48 00 68 01 21
			c9 04 88 43 02 49 08 60 70 47 00 00 00 60 00 40
			00 70 00 40 03 48 00 68 01 21 89 05 88 43 01 49
			08 60 70 47 00 70 00 40 30 b4 74 46 64 1e 25 78
			64 1c ab 42 04 d3 63 5d 5b 00 e3 18 30 bc 18 47
			1d 46 f8 e7 10 b5 fe 48 00 78 08 28 0b da 01 f0
			ef fa fc 49 fa 4a 12 78 88 54 f9 48 00 78 40 1c
			f7 49 08 70 10 bd f6 48 00 78 08 28 29 d1 09 20
			f3 49 08 70 01 f0 ee fd f2 48 00 78 01 28 21 d1
			f0 48 40 78 00 28 1d d1 ee 48 80 78 01 28 19 d1
			ec 48 c0 78 c0 00 eb 49 09 79 89 00 08 43 e9 49
			49 79 49 00 08 43 e7 49 89 79 08 43 e6 49 08 70
			00 20 e6 49 08 70 e6 48 00 78 00 28 d6 d1 e5 49
			08 70 8f e0 df 48 00 78 01 28 20 d1 dd 48 40 78
			00 28 1c d1 db 48 80 78 00 28 18 d1 d9 48 c0 78
			c0 00 d8 49 09 79 89 00 08 43 d6 49 49 79 49 00
			08 43 d4 49 89 79 08 43 d3 49 08 70 00 20 d3 49
			08 70 d3 49 08 70 02 20 d2 49 08 70 6a e0 cd 48
			40 78 01 28 21 d1 cb 48 80 78 00 28 1d d1 c9 48
			c0 78 01 28 19 d1 c7 48 00 79 c0 00 c5 49 49 79
			89 00 08 43 c3 49 89 79 49 00 08 43 c1 49 c9 79
			08 43 c1 49 08 70 00 20 c0 49 08 70 c0 48 00 78
			00 28 01 d1 bf 49 08 70 84 e7 ba 48 40 78 01 28
			20 d1 b8 48 80 78 00 28 1c d1 b6 48 c0 78 00 28
			18 d1 b4 48 00 79 c0 00 b2 49 49 79 89 00 08 43
			b0 49 89 79 49 00 08 43 ae 49 c9 79 08 43 ae 49
			08 70 00 20 ad 49 08 70 ad 49 08 70 02 20 ad 49
			08 70 5f e7 a7 48 c0 78 c0 00 a6 49 09 79 89 00
			08 43 a4 49 49 79 49 00 08 43 a2 49 89 79 08 43
			a1 49 08 70 02 20 a3 49 08 70 a0 48 00 78 00 28
			05 d1 9e 48 00 78 40 1c 9c 49 08 70 02 e0 01 20
			9d 49 08 70 9d 48 00 78 00 28 14 d1 9c 49 c8 70
			08 71 48 71 88 71 c8 71 08 72 48 72 99 48 00 78
			02 28 09 d1 90 48 00 78 00 07 00 0e 96 49 08 70
			01 20 93 49 48 71 3e e2 92 48 00 78 01 28 0a d1
			91 48 00 78 88 49 09 78 08 43 8f 49 08 70 01 20
			8b 49 48 71 2f e2 8d 48 00 78 05 28 16 d1 88 48
			80 7a 87 49 c8 70 08 46 c0 7a 08 71 08 46 00 7b
			48 71 08 46 40 7b 88 71 08 46 80 7b c8 71 08 46
			c0 7b 08 72 08 46 00 7c 48 72 14 e2 7f 48 00 78
			04 28 09 d1 74 48 00 78 00 07 00 0c 7c 49 08 80
			01 20 77 49 48 71 06 e2 78 48 00 78 03 28 0b d1
			6d 48 00 78 00 02 76 49 09 88 08 43 74 49 08 80
			01 20 6f 49 48 71 f6 e1 70 48 00 78 02 28 0b d1
			65 48 00 78 00 01 6e 49 09 88 08 43 6c 49 08 80
			01 20 67 49 48 71 e6 e1 68 48 00 78 01 28 15 d1
			67 48 00 88 5c 49 09 78 08 43 65 49 08 80 00 f0
			a1 fb 01 20 5e 49 48 71 62 48 00 88 60 49 09 88
			88 42 90 d1 01 20 60 49 08 70 cc e1 5f 48 00 78
			00 28 4c d0 5d 48 00 78 40 1e c1 00 08 1a 5c 49
			09 68 08 5c 52 49 c8 70 58 48 00 78 40 1e c1 00
			08 1a 57 49 09 68 40 18 40 78 4d 49 08 71 53 48
			00 78 40 1e c1 00 08 1a 51 49 09 68 40 18 80 78
			47 49 48 71 4d 48 00 78 40 1e c1 00 08 1a 4c 49
			09 68 40 18 c0 78 42 49 88 71 48 48 00 78 40 1e
			c1 00 08 1a 46 49 09 68 40 18 00 79 3c 49 c8 71
			42 48 00 78 40 1e c1 00 08 1a 41 49 09 68 40 18
			40 79 37 49 08 72 3d 48 00 78 40 1e c1 00 08 1a
			3b 49 09 68 40 18 80 79 31 49 48 72 7b e1 2a 48
			00 78 09 28 0c d1 00 20 2e 49 08 70 2f 49 08 70
			32 49 08 70 01 f0 22 f9 01 20 32 49 08 70 51 e6
			00 20 28 49 08 70 29 49 08 70 2c 49 08 70 1e 48
			00 78 03 00 ff f7 28 fe 10 f3 09 84 9e d4 e7 20
			20 20 20 20 20 f4 f1 f0 ef 20 27 48 00 78 00 28
			13 d0 26 48 00 78 00 28 06 d1 01 20 18 49 c8 70
			08 71 08 72 48 72 02 e0 01 20 15 49 88 71 1f 48
			00 78 c0 43 1d 49 08 70 3c e1 1d 48 00 78 00 28
			38 d0 01 20 0e 49 c8 70 08 71 48 71 88 71 c8 71
			08 72 48 72 16 48 00 78 40 1e 15 49 08 70 29 e1
			21 00 00 20 19 00 00 20 23 00 00 20 15 00 00 20
			60 00 00 20 5f 00 00 20 12 00 00 20 22 00 00 20
			70 00 00 20 25 00 00 20 26 00 00 20 28 00 00 20
			2c 00 00 20 2e 00 00 20 30 00 00 20 29 00 00 20
			00 00 00 20 18 00 00 20 37 00 00 20 5e 00 00 20
			58 00 00 20 af 48 00 68 af 49 88 42 01 da 00 24
			07 e0 ac 49 09 68 ac 4a 88 1a 0a 21 ff f7 84 f9
			04 46 60 06 c0 0f a9 49 c8 70 a0 06 c0 0f 08 71
			e0 06 c0 0f 48 71 20 07 c0 0f 88 71 60 07 c0 0f
			c8 71 a0 07 c0 0f 08 72 e0 07 c0 0f 48 72 d9 e0
			09 21 08 20 01 f0 7c fe 9d 49 08 70 08 46 00 78
			02 28 03 d1 01 20 99 49 08 71 0a e0 98 48 00 78
			01 28 03 d1 95 49 08 71 48 71 02 e0 01 20 93 49
			48 71 bf e0 01 20 93 49 08 70 93 48 00 78 40 06
			c0 0f 8e 49 c8 70 90 48 00 78 80 06 c0 0f 08 71
			8d 48 00 78 c0 06 c0 0f 48 71 8b 48 00 78 00 07
			c0 0f 88 71 88 48 00 78 40 07 c0 0f c8 71 86 48
			00 78 80 07 c0 0f 08 72 83 48 00 78 c0 07 c0 0f
			48 72 00 20 81 49 08 70 7f 48 00 78 64 21 48 43
			ff 30 2d 30 7e 49 08 80 0a 20 7e 49 08 70 89 e0
			7d 48 00 78 00 28 07 d0 00 20 7c 49 08 70 7a 48
			00 78 40 1e 78 49 08 70 78 48 00 78 6f 49 c8 70
			01 20 48 71 76 e0 03 20 75 49 08 70 01 20 6b 49
			08 71 88 71 6e e0 35 e0 33 e0 19 e0 00 e0 2f e0
			70 48 00 78 00 28 03 d0 6f 48 00 78 00 28 00 d1
			60 e0 6c 48 00 78 40 1e 6a 49 08 70 06 20 6b 49
			08 70 01 f0 49 f8 6a 49 08 70 00 f0 c1 f9 51 e0
			68 48 00 78 40 1c 68 49 08 70 66 48 00 78 80 1c
			66 49 08 70 66 48 00 78 54 49 c8 70 65 48 00 78
			08 71 65 48 00 78 48 71 64 48 00 78 88 71 39 e0
			01 e0 00 e0 00 bf 62 48 00 78 00 28 2f d0 4d 48
			00 78 00 28 2b d0 5f 48 00 78 03 28 03 d1 01 20
			5d 49 08 70 0e e5 5b 48 00 78 40 1c 59 49 08 70
			40 49 09 68 40 4a 88 1a 0a 21 ff f7 ad f8 04 46
			60 06 c0 0f 3d 49 c8 70 a0 06 c0 0f 08 71 e0 06
			c0 0f 48 71 20 07 c0 0f 88 71 60 07 c0 0f c8 71
			a0 07 c0 0f 08 72 e0 07 c0 0f 48 72 02 e0 01 f0
			95 fb e7 e4 00 bf 31 49 48 4a 12 78 88 5c 01 f0
			ef fa 46 48 00 78 40 1c 44 49 08 70 08 46 00 78
			09 28 4c dd 04 20 00 f0 83 fb 01 20 00 f0 80 fb
			01 f0 b2 fa 00 20 3d 49 08 70 3d 49 08 70 3d 49
			08 70 2b 48 00 78 00 28 05 d0 29 48 00 78 40 1e
			27 49 08 70 33 e0 29 48 00 78 00 28 05 d0 27 48
			00 78 40 1e 25 49 08 70 29 e0 27 48 00 78 00 28
			0a d0 25 48 00 78 40 1e 23 49 08 70 23 48 00 78
			40 1e 22 49 08 70 1a e0 2b 48 00 78 02 28 02 d0
			04 28 13 d1 0a e0 0e 48 00 78 01 28 05 d1 13 48
			00 78 01 28 01 d1 00 f0 61 ff 07 e0 01 20 12 49
			08 70 00 f0 99 ff 21 49 08 70 00 bf 00 bf 00 bf
			88 e4 00 00 0c 00 00 20 4c 0d 00 00 70 00 00 20
			6c 00 00 20 14 00 00 20 59 00 00 20 58 00 00 20
			62 00 00 20 64 00 00 20 60 00 00 20 17 00 00 20
			25 00 00 20 27 00 00 20 34 00 00 20 28 00 00 20
			36 00 00 20 04 00 00 20 29 00 00 20 2a 00 00 20
			06 00 00 20 07 00 00 20 08 00 00 20 09 00 00 20
			67 00 00 20 16 00 00 20 13 00 00 20 22 00 00 20
			21 00 00 20 24 00 00 20 23 00 00 20 35 00 00 20
			10 b5 5d 48 00 78 08 28 0b da 00 f0 29 ff 5b 49
			59 4a 12 78 88 54 58 48 00 78 40 1c 56 49 08 70
			10 bd 55 48 00 78 08 28 61 d1 09 20 52 49 08 70
			01 f0 28 fa 51 48 00 78 01 28 1b d1 4f 48 40 78
			00 28 17 d1 4d 48 80 78 01 28 13 d1 4b 48 c0 78
			c0 00 4a 49 09 79 89 00 08 43 48 49 49 79 49 00
			08 43 46 49 89 79 08 43 45 49 08 70 00 20 45 49
			08 70 3c e0 41 48 40 78 01 28 1b d1 3f 48 80 78
			00 28 17 d1 3d 48 c0 78 01 28 13 d1 3b 48 00 79
			c0 00 3a 49 49 79 89 00 08 43 38 49 89 79 49 00
			08 43 36 49 c9 79 08 43 35 49 08 70 00 20 35 49
			08 70 b5 e7 31 48 c0 78 c0 00 30 49 09 79 89 00
			08 43 2e 49 49 79 49 00 08 43 2c 49 89 79 08 43
			2b 49 08 70 2b 48 00 78 00 28 05 d1 29 48 00 78
			40 1c 28 49 08 70 02 e0 01 20 27 49 08 70 27 48
			00 78 00 28 22 d1 01 20 25 49 88 70 00 20 c8 70
			08 71 48 71 88 71 c8 71 08 72 48 72 1c 48 00 78
			04 28 02 d0 06 28 0c d1 07 e0 1e 48 00 78 1c 49
			c8 70 01 20 c8 71 48 72 07 e0 01 20 18 49 c8 70
			03 e0 01 20 18 49 08 70 72 e7 00 bf 14 49 13 4a
			12 78 88 5c 01 f0 b4 f9 10 48 00 78 40 1c 0f 49
			08 70 08 46 00 78 09 28 0b dd 04 20 00 f0 48 fa
			01 f0 7a f9 00 20 09 49 08 70 03 49 08 70 0b 49
			08 70 00 bf 54 e7 00 00 21 00 00 20 19 00 00 20
			23 00 00 20 15 00 00 20 12 00 00 20 22 00 00 20
			70 00 00 20 17 00 00 20 13 00 00 20 24 00 00 20
			28 48 00 78 40 02 28 49 09 78 49 00 08 43 27 49
			08 80 24 48 00 78 40 06 c0 0f 25 49 48 71 21 48
			00 78 80 06 c0 0f c8 72 1e 48 00 78 c0 06 c0 0f
			08 72 1c 48 00 78 00 07 c0 0f 08 74 19 48 00 78
			40 07 c0 0f 88 73 17 48 00 78 80 07 c0 0f 48 73
			14 48 00 78 c0 07 c0 0f c8 71 13 48 00 78 40 06
			c0 0f c8 70 10 48 00 78 80 06 c0 0f 08 73 0e 48
			00 78 c0 06 c0 0f 08 71 0b 48 00 78 00 07 c0 0f
			88 72 09 48 00 78 40 07 c0 0f 48 72 06 48 00 78
			80 07 c0 0f c8 73 04 48 00 78 c0 07 c0 0f 88 71
			70 47 00 00 35 00 00 20 36 00 00 20 2e 00 00 20
			70 00 00 20 03 48 00 88 03 49 08 40 01 49 08 80
			70 47 00 00 2c 00 00 20 fe fe 00 00 10 b5 01 46
			00 22 0b 20 01 23 83 40 36 4c 23 60 00 bf 02 29
			07 d1 35 48 00 68 8b 03 98 43 c0 18 32 4b 18 60
			06 e0 31 48 00 68 01 23 db 03 98 43 2e 4b 18 60
			03 29 08 d1 2c 48 00 68 01 23 9b 03 98 43 c0 18
			29 4b 18 60 06 e0 28 48 00 68 01 23 9b 03 98 43
			25 4b 18 60 04 29 07 d1 23 48 00 68 cb 02 98 43
			c0 18 21 4b 18 60 06 e0 1f 48 00 68 01 23 5b 03
			98 43 1d 4b 18 60 05 29 08 d1 1b 48 00 68 01 23
			1b 03 98 43 c0 18 18 4b 18 60 06 e0 16 48 00 68
			01 23 1b 03 98 43 14 4b 18 60 13 48 00 68 f0 23
			98 43 0b 01 f0 24 23 40 18 43 0f 4b 18 60 18 46
			00 68 02 23 98 43 80 1c 0b 4b 18 60 18 46 00 68
			40 08 40 00 40 1c 18 60 06 e0 07 48 00 68 c0 07
			c0 0f 00 28 00 d1 00 e0 f7 e7 00 bf 02 48 42 68
			90 b2 10 bd 00 e1 00 e0 00 40 00 40 70 47 70 47
			78 b5 05 46 00 26 0f e0 6a 46 02 21 28 46 fe f7
			99 ff 01 28 00 d1 09 e0 4b 20 c0 01 fe f7 d8 ff
			00 20 00 90 70 1c c6 b2 03 2e ed db 00 bf 69 46
			48 78 00 02 09 78 08 43 04 b2 06 2d 02 d1 02 48
			20 18 04 b2 20 46 78 bd 55 f5 ff ff fe b5 20 a0
			00 68 02 90 00 20 00 90 23 e0 02 aa 02 21 3e 20
			fe f7 bb ff 06 46 01 2e 11 d1 00 f0 03 f9 01 aa
			04 21 40 20 fe f7 66 ff 07 46 01 2f 00 d1 13 e0
			4b 20 c0 01 fe f7 a4 ff 00 20 01 90 05 e0 4b 20
			c0 01 fe f7 9d ff 00 20 01 90 00 98 40 1c c0 b2
			00 90 00 98 03 28 d8 db 00 bf 68 46 40 79 04 02
			68 46 00 79 04 43 68 46 c0 79 05 02 69 46 89 79
			0d 43 ac 42 01 da 28 46 fe bd 20 46 fc e7 00 00
			71 00 00 00 00 b5 02 20 ff f7 18 ff 0f 49 88 42
			0b db 03 20 ff f7 12 ff 0c 49 88 42 05 db 04 20
			ff f7 0c ff 09 49 88 42 05 da 09 48 00 78 40 1c
			07 49 08 70 02 e0 00 20 05 49 08 70 04 48 00 78
			09 28 01 dd 01 20 00 bd 00 20 fc e7 41 08 00 00
			5d 00 00 20 10 b5 04 46 00 2c 02 d0 00 20 00 f0
			69 ff 00 21 10 20 ff f7 93 f8 10 20 ff f7 4a f8
			13 48 00 68 80 21 88 43 11 49 08 60 11 48 00 69
			04 21 88 43 0f 49 08 61 08 46 00 69 40 08 40 00
			40 1c 08 61 08 46 00 69 ff 21 81 31 88 43 80 30
			08 49 08 61 08 46 00 69 49 15 88 43 40 18 05 49
			08 61 00 2c 02 d0 01 20 00 f0 3c ff 10 bd 00 00
			00 70 00 40 00 50 00 40 10 b5 04 46 00 2c 02 d0
			00 20 00 f0 2f ff 00 21 0e 20 ff f7 59 f8 0e 20
			ff f7 10 f8 13 48 00 68 01 21 49 02 88 43 11 49
			08 60 11 48 00 68 04 21 88 43 0f 49 08 60 08 46
			00 68 40 08 40 00 40 1c 08 60 08 46 00 68 ff 21
			81 31 88 43 80 30 08 49 08 60 08 46 00 68 49 15
			88 43 40 18 04 49 08 60 00 2c 02 d0 01 20 00 f0
			01 ff 10 bd 00 70 00 40 00 50 00 40 08 b5 0a 20
			00 90 01 e0 00 f0 06 f8 00 98 41 1e 00 91 00 28
			f8 d1 08 bd 08 b5 05 48 00 90 00 e0 00 bf 00 98
			41 1e 00 91 00 28 f9 d1 08 bd 00 00 ed 08 00 00
			08 b5 05 48 00 90 00 e0 00 bf 00 98 41 1e 00 91
			00 28 f9 d1 08 bd 00 00 88 13 00 00 08 b5 2c 20
			00 90 00 e0 00 bf 00 98 41 1e 00 91 00 28 f9 d1
			08 bd 00 00 08 b5 05 48 00 90 00 e0 00 bf 00 98
			41 1e 00 91 00 28 f9 d1 08 bd 00 00 37 02 00 00
			10 b5 02 46 14 46 03 e0 ff f7 ec ff 60 1e c4 b2
			00 2c f9 dc 10 bd 70 47 8a b0 00 20 09 90 08 90
			00 26 00 27 07 90 06 90 05 90 04 90 03 90 02 90
			01 90 e1 20 40 01 fe 49 08 80 c0 10 fd 49 08 80
			fd 48 fe 49 08 60 fe 49 08 60 0a 20 fd 49 08 70
			81 e3 01 f0 0d fa fc 48 00 68 00 28 43 d1 58 20
			01 f0 24 f8 05 46 f9 48 00 78 00 28 36 d1 1f 2d
			05 d1 00 f0 e3 fb 01 20 f4 49 08 70 21 e0 00 2d
			03 d1 71 20 00 f0 9c ff 1b e0 0c 2d 06 dd 10 2d
			04 da a8 00 28 18 c0 b2 00 90 12 e0 01 2d 07 dd
			0c 2d 05 da 68 1c 81 00 40 18 c0 b2 00 90 08 e0
			0c 2d 02 d1 3f 20 00 90 03 e0 01 2d 01 d1 0f 20
			00 90 e3 48 00 78 00 28 08 d1 e2 48 02 78 e2 48
			00 78 00 99 00 f0 48 ff dd 49 08 70 7d 20 00 01
			d9 49 08 60 34 e3 d5 48 00 68 00 28 70 d1 0c 20
			ff f7 3e fe 07 46 d9 48 87 42 05 dd ff f7 58 ff
			0c 20 ff f7 35 fe 07 46 3c 46 00 bf cf 48 00 78
			00 28 72 d1 d2 48 84 42 0a da 07 98 40 1c c0 b2
			07 90 07 98 02 28 05 dd 77 20 00 f0 49 ff 01 e0
			00 20 07 90 c9 48 87 42 02 dd 75 20 00 f0 40 ff
			c8 48 84 42 0a dd 03 98 40 1c c0 b2 03 90 03 98
			02 28 05 dd 74 20 00 f0 33 ff 01 e0 00 20 03 90
			c1 48 00 78 01 28 53 d1 c0 48 00 68 c0 49 88 42
			02 dd 05 20 06 90 25 e0 bc 48 00 68 bc 49 49 1f
			88 42 02 dd 04 20 06 90 1c e0 b8 48 00 68 b8 49
			14 39 88 42 02 dd 03 20 06 90 13 e0 b3 48 00 68
			b3 49 1e 39 88 42 02 dd 02 20 06 90 0a e0 af 48
			00 68 af 49 28 39 88 42 02 dd 01 20 06 90 01 e0
			00 20 06 90 ab 48 84 42 03 dd 00 20 05 90 d0 e0
			15 e1 a8 48 64 38 84 42 02 dd 01 20 05 90 c8 e0
			a4 48 c8 38 84 42 02 dd 02 20 05 90 c1 e0 a2 48
			84 42 03 dd 03 20 05 90 bb e0 f7 e0 9e 48 64 38
			84 42 02 dd 04 20 05 90 b3 e0 05 20 05 90 b0 e0
			95 48 00 78 02 28 51 d1 94 48 00 68 94 49 88 42
			02 dd 05 20 06 90 25 e0 90 48 00 68 90 49 49 1f
			88 42 02 dd 04 20 06 90 1c e0 8c 48 00 68 8c 49
			14 39 88 42 02 dd 03 20 06 90 13 e0 87 48 00 68
			87 49 1e 39 88 42 02 dd 02 20 06 90 0a e0 83 48
			00 68 83 49 28 39 88 42 02 dd 01 20 06 90 01 e0
			00 20 06 90 7f 48 64 30 84 42 02 dd 00 20 05 90
			77 e0 7c 48 84 42 02 dd 01 20 05 90 71 e0 79 48
			64 38 84 42 02 dd 02 20 05 90 6a e0 76 48 64 30
			84 42 02 dd 03 20 05 90 63 e0 73 48 84 42 02 dd
			04 20 05 90 5d e0 05 20 05 90 5a e0 6a 48 00 78
			03 28 52 d1 69 48 00 68 6c 49 88 42 02 dd 05 20
			06 90 25 e0 65 48 00 68 68 49 3c 39 88 42 02 dd
			04 20 06 90 1c e0 61 48 00 68 64 49 64 39 88 42
			02 dd 03 20 06 90 13 e0 5c 48 00 68 7d 21 49 01
			88 42 02 dd 02 20 06 90 0a e0 58 48 00 68 5b 49
			a0 39 88 42 02 dd 01 20 06 90 01 e0 00 20 06 90
			54 48 84 42 02 dd 00 20 05 90 22 e0 19 20 40 01
			84 42 02 dd 01 20 05 90 1b e0 4b 20 c0 00 84 42
			02 dd 02 20 05 90 14 e0 ff 20 c3 30 84 42 02 dd
			03 20 05 90 0d e0 ff 20 2d 30 84 42 02 dd 04 20
			05 90 06 e0 05 20 05 90 03 e0 00 20 06 90 05 20
			05 90 05 99 06 98 40 18 05 28 0a dd 02 98 40 1c
			c0 b2 02 90 02 98 05 28 05 dd 5a 20 00 f0 18 fe
			01 e0 00 20 02 90 3a 48 00 88 84 42 11 dd 38 48
			00 88 38 49 88 42 0c dd 37 48 00 78 00 28 05 d0
			35 48 00 78 40 1e 34 49 08 70 02 e0 55 20 00 f0
			ff fd 2a 48 00 68 2a 49 24 39 88 42 0f dd 2f 48
			84 42 0c dd 1b 48 00 78 40 1e 1a 49 08 70 08 46
			00 78 00 28 06 d1 55 20 00 f0 ea fd 02 e0 0a 20
			14 49 08 70 7d 20 c0 00 10 49 08 60 a8 e1 24 48
			00 68 00 28 7e d1 ff f7 d9 fc 06 46 21 48 86 42
			03 dc 7d 20 00 01 86 42 43 da ff f7 c9 fd ff f7
			cd fc 06 46 1b 48 86 42 38 dc 7d 20 00 01 33 e0
			3c 00 00 20 3e 00 00 20 20 4e 00 00 44 00 00 20
			50 00 00 20 65 00 00 20 48 00 00 20 37 00 00 20
			58 00 00 20 33 00 00 20 5a 00 00 20 10 27 00 00
			30 f8 ff ff 34 21 00 00 0b 00 00 20 0c 00 00 20
			8a 11 00 00 b6 03 00 00 8a 02 00 00 22 10 00 00
			62 00 00 20 fc 08 00 00 64 00 00 20 ac 0d 00 00
			40 00 00 20 88 13 00 00 86 42 02 da 76 20 00 f0
			8f fd ad 48 06 60 ad 48 00 78 00 28 7e d1 ac 48
			00 88 00 28 07 d1 ab 48 00 78 28 28 1e dd 28 20
			a8 49 08 70 1a e0 a6 48 00 88 ff 21 e1 31 88 42
			07 da a4 48 00 78 32 28 10 dd 32 20 a1 49 08 70
			0c e0 9f 48 00 88 2d 21 09 01 88 42 06 da 9d 48
			00 78 3c 28 02 dd 3c 20 9a 49 08 70 9a 48 00 78
			00 28 00 e0 a0 e0 19 d1 93 48 00 68 97 49 88 42
			07 dd 94 48 00 78 49 28 10 dd 49 20 91 49 08 70
			0c e0 8d 48 00 68 91 49 fa 39 88 42 06 dd 8d 48
			00 78 49 28 02 dd 49 20 8a 49 08 70 86 48 00 68
			8a 49 96 39 88 42 07 dd 86 48 00 78 49 28 1e dd
			49 20 84 49 08 70 1a e0 7f 48 00 68 21 21 c9 01
			88 42 07 dd 7f 48 00 78 49 28 10 dd 49 20 7d 49
			08 70 0c e0 78 48 00 68 7c 49 e6 39 88 42 06 dd
			78 48 00 78 49 28 02 dd 49 20 76 49 08 70 78 48
			00 78 00 28 09 d1 77 48 02 78 77 48 01 78 71 48
			00 78 00 f0 e1 fc 72 49 08 70 00 e0 44 e0 73 48
			00 78 02 28 08 d1 68 48 00 68 6c 49 14 39 88 42
			02 dd 5a 20 00 f0 fc fc 6d 48 00 78 01 28 1a d1
			61 48 00 68 6b 49 88 42 02 dd 5a 20 00 f0 f0 fc
			5d 48 00 68 67 49 0a 39 88 42 0a dd 08 98 40 1c
			c0 b2 08 90 08 98 05 28 05 dd 5a 20 00 f0 e0 fc
			01 e0 00 20 08 90 54 48 00 68 58 49 32 31 88 42
			02 dd 5a 20 00 f0 d4 fc 4f 48 00 68 53 49 28 31
			88 42 0a dd 09 98 40 1c c0 b2 09 90 09 98 05 28
			05 dd 5a 20 00 f0 c4 fc 01 e0 00 20 09 90 ff 20
			f5 30 51 49 08 60 83 e0 50 48 00 68 00 28 2a d1
			06 20 ff f7 8d fb 04 46 40 48 00 78 00 28 1d d1
			00 2c 0e dd 46 48 00 78 00 28 03 d1 ff 20 f5 30
			84 42 06 dc 42 48 00 78 01 28 0d d1 44 48 84 42
			0a dd 04 98 40 1c c0 b2 04 90 04 98 02 28 05 dd
			5c 20 00 f0 95 fc 01 e0 00 20 04 90 ff 20 f5 30
			3a 49 08 60 54 e0 3b 48 00 68 00 28 1e d1 2b 48
			00 78 00 28 0e d1 ff f7 c5 fb 00 28 05 d0 00 20
			00 f0 bc f8 01 20 25 49 08 70 19 20 40 01 31 49
			08 60 3d e0 01 98 00 28 04 d1 5d 20 00 f0 e6 fc
			01 20 01 90 2c 48 2b 49 08 60 31 e0 2b 48 00 78
			00 28 2d d1 2a 48 00 88 00 28 06 d1 17 48 00 78
			00 28 02 d1 5a 20 00 f0 5b fc 26 48 00 78 00 28
			02 d0 59 20 00 f0 54 fc 23 48 00 78 00 28 02 d0
			73 20 00 f0 4d fc 21 48 00 78 00 28 02 d0 72 20
			00 f0 46 fc 1e 48 00 78 00 28 03 d1 1d 48 00 78
			01 28 02 dd 54 20 00 f0 3b fc 14 20 13 49 08 70
			2f 20 ff f7 55 fc 7c e4 0c 00 00 20 37 00 00 20
			3e 00 00 20 5a 00 00 20 5b 00 00 20 62 11 00 00
			58 00 00 20 33 00 00 20 32 00 00 20 66 00 00 20
			0a 00 00 20 2c 10 00 00 40 00 00 20 50 00 00 20
			26 02 00 00 54 00 00 20 10 27 00 00 4c 00 00 20
			3c 00 00 20 18 00 00 20 13 00 00 20 12 00 00 20
			10 00 00 20 61 00 00 20 30 e0 00 f0 59 fe 18 48
			00 68 00 28 0a d1 58 20 00 f0 70 fc 00 28 01 d1
			00 f0 06 fc 13 48 12 49 08 60 1f e0 12 48 00 78
			00 28 1b d1 11 48 00 78 00 28 02 d0 73 20 00 f0
			e7 fb 0f 48 00 78 00 28 02 d0 72 20 00 f0 e0 fb
			0c 48 00 78 00 28 03 d1 0b 48 00 78 01 28 02 dd
			54 20 00 f0 d5 fb 14 20 03 49 08 70 cd e7 00 00
			48 00 00 20 70 17 00 00 4c 00 00 20 13 00 00 20
			12 00 00 20 10 00 00 20 61 00 00 20 00 28 07 d0
			08 49 09 6b 80 22 91 43 80 31 06 4a 11 63 05 e0
			04 49 09 6b 80 22 91 43 02 4a 11 63 02 49 08 70
			70 47 00 00 00 40 00 40 67 00 00 20 70 47 00 00
			02 49 49 69 49 06 c8 0f 70 47 00 00 00 50 00 40
			02 49 49 68 49 06 c8 0f 70 47 00 00 00 50 00 40
			03 48 00 6b 00 06 c0 0f 01 21 48 40 70 47 00 00
			00 40 00 40 00 b5 09 20 ff f7 e8 f9 01 49 08 60
			00 bd 00 00 68 00 00 20 02 49 89 68 c8 b2 40 06
			40 0e 70 47 00 10 00 40 18 48 40 69 80 21 88 43
			16 49 48 61 08 46 80 69 88 61 15 48 00 68 01 21
			c9 05 88 43 12 49 08 60 00 20 01 21 81 40 11 4a
			11 60 00 bf 0d 48 00 68 fe 21 88 43 1c 30 0b 49
			08 60 08 46 40 69 20 21 88 43 20 30 07 49 48 61
			08 46 40 69 10 21 88 43 04 49 48 61 08 46 40 69
			80 21 88 43 80 30 01 49 48 61 70 47 00 30 00 40
			00 70 00 40 00 e1 00 e0 00 f0 30 fa 00 f0 c2 fc
			00 f0 8e fd 00 f0 94 fd 00 f0 29 fa ff f7 bc ff
			00 20 ff f7 d9 fa 01 20 00 f0 0c fa 53 20 00 f0
			2d fc 05 46 2d 07 2d 0f 00 2d 01 d1 0a 24 16 e0
			01 2d 01 d1 3c 24 12 e0 02 2d 01 d1 82 24 0e e0
			03 2d 01 d1 aa 24 0a e0 04 2d 02 d1 ff 24 05 34
			05 e0 05 2d 02 d1 ff 24 f5 34 00 e0 0a 24 32 2c
			0b db 78 2c 09 da d7 48 d7 49 08 60 04 20 d7 49
			08 70 02 20 d6 49 08 70 48 e0 78 2c 0b db a0 2c
			09 da d4 48 d0 49 08 60 06 20 d0 49 08 70 01 20
			d1 49 08 70 3a e0 a0 2c 0b db fa 2c 09 da cf 48
			c9 49 08 60 08 20 c9 49 08 70 01 20 ca 49 08 70
			2c e0 fa 2c 0d db ff 20 af 30 84 42 09 da c8 48
			c1 49 08 60 08 20 c1 49 08 70 02 20 c2 49 08 70
			1c e0 ff 20 af 30 84 42 0f db c2 48 84 42 0c da
			c1 48 b9 49 08 60 02 20 b8 49 08 70 01 20 bf 49
			08 70 03 20 b8 49 08 70 08 e0 bd 48 b2 49 08 60
			04 20 b2 49 08 70 02 20 b1 49 08 70 af 49 08 78
			c1 0f 09 18 49 10 b7 4a 11 70 10 46 00 78 08 21
			08 40 c0 10 b4 49 08 70 10 46 00 78 04 21 08 40
			80 10 b2 49 08 70 10 46 00 78 02 21 08 40 40 10
			af 49 08 70 10 46 00 78 c0 07 c0 0f ad 49 08 70
			00 f0 c6 fa 00 f0 dc fa 00 f0 e6 f9 00 f0 8e f9
			00 21 0b 20 fe f7 58 fa 00 20 ff f7 f3 f9 00 bf
			ff f7 b1 fa 00 f0 dc fc 00 f0 f0 fa 00 28 f7 d0
			11 e0 00 f0 d5 fc a0 48 00 78 00 28 01 d0 00 f0
			87 fa 9e 48 00 78 01 28 00 d1 05 e0 9c 48 00 78
			00 28 00 d1 00 e0 ec e7 00 bf 52 20 00 f0 de fa
			05 46 01 20 97 49 08 70 00 2d 01 d1 00 f0 70 fa
			00 f0 b6 fc 16 e0 00 f0 b3 fc 8f 48 00 78 00 28
			02 d0 54 20 00 f0 54 fa 8c 48 00 78 01 28 04 d1
			8d 48 00 78 01 28 00 d1 05 e0 89 48 00 78 00 28
			00 d1 00 e0 e7 e7 00 bf 01 20 88 49 08 70 ff f7
			15 f9 87 48 00 78 00 f0 b1 fa 05 46 02 2d 01 d0
			00 f0 46 fa 00 f0 8c fc 00 f0 8a fc 80 48 00 78
			00 28 03 d0 ff f7 2a f9 7e 49 08 60 ff f7 06 fa
			7b 48 00 78 00 28 03 d0 2c 20 ff f7 f9 f8 c6 b2
			55 2e 25 dd fa 2c 05 db 14 20 77 49 08 70 77 49
			08 70 8a e0 a0 2c 05 db 0f 20 73 49 08 70 73 49
			08 70 82 e0 78 2c 05 db 0a 20 6f 49 08 70 6f 49
			08 70 7a e0 32 2c 05 db 0a 20 6b 49 08 70 6b 49
			08 70 72 e0 0a 20 68 49 08 70 68 49 08 70 6c e0
			4b 2e 25 dd fa 2c 05 db 1e 20 63 49 08 70 63 49
			08 70 62 e0 a0 2c 05 db 19 20 5f 49 08 70 5f 49
			08 70 5a e0 78 2c 05 db 14 20 5b 49 08 70 5b 49
			08 70 52 e0 32 2c 05 db 0a 20 57 49 08 70 57 49
			08 70 4a e0 0a 20 54 49 08 70 54 49 08 70 44 e0
			32 2e 25 dd fa 2c 05 db 28 20 4f 49 08 70 4f 49
			08 70 3a e0 a0 2c 05 db 28 20 4b 49 08 70 4b 49
			08 70 32 e0 78 2c 05 db 1c 20 47 49 08 70 47 49
			08 70 2a e0 32 2c 05 db 0f 20 43 49 08 70 43 49
			08 70 22 e0 0a 20 40 49 08 70 40 49 08 70 1c e0
			a0 2c 05 db 49 20 3c 49 08 70 3c 49 08 70 14 e0
			78 2c 05 db 32 20 38 49 08 70 38 49 08 70 0c e0
			32 2c 05 db 19 20 34 49 08 70 34 49 08 70 04 e0
			14 20 31 49 08 70 31 49 08 70 20 48 00 78 01 28
			04 d1 0c 20 2c 49 08 70 2c 49 08 70 ff f7 5e f9
			ff f7 f0 fd 58 20 00 f0 f1 f9 01 20 28 49 08 70
			1f 48 00 78 00 28 01 d1 ff f7 6e fd 0c e0 00 f0
			c7 fb 19 48 00 78 00 28 03 d1 1a 48 00 78 01 28
			02 dd 54 20 00 f0 64 f9 ff f7 ca fd 01 28 ee d0
			ff f7 8a f9 28 2c 00 00 00 00 00 20 04 00 00 20
			66 00 00 20 44 2c 00 00 0b 00 00 20 6e 2c 00 00
			a6 2c 00 00 12 02 00 00 de 2c 00 00 0a 00 00 20
			0c 2c 00 00 05 00 00 20 06 00 00 20 07 00 00 20
			08 00 00 20 09 00 00 20 10 00 00 20 30 00 00 20
			5f 00 00 20 61 00 00 20 2a 00 00 20 31 00 00 20
			26 00 00 20 0c 00 00 20 59 00 00 20 5a 00 00 20
			17 00 00 20 00 28 06 d0 07 49 09 78 00 29 02 d1
			05 49 08 70 07 e0 00 28 05 d1 03 49 09 78 00 29
			01 d0 01 49 08 70 70 47 6e 00 00 20 70 47 00 b5
			ff f7 64 fd 00 f0 a0 f8 00 f0 48 f8 00 f0 5c f8
			00 f0 04 f8 fe f7 db ff 00 bd 00 00 09 48 00 69
			04 21 88 43 07 49 08 61 08 46 00 69 30 21 88 43
			04 49 08 61 08 46 00 69 40 08 40 00 40 1c 08 61
			70 47 00 00 00 50 00 40 09 48 00 69 40 08 40 00
			07 49 08 61 08 46 00 69 04 21 88 43 00 1d 04 49
			08 61 08 46 00 69 02 21 88 43 01 49 08 61 70 47
			00 50 00 40 00 28 07 d0 07 49 09 69 02 22 91 43
			89 1c 05 4a 11 61 05 e0 03 49 09 69 02 22 91 43
			01 4a 11 61 70 47 00 00 00 50 00 40 09 48 00 68
			04 21 88 43 07 49 08 60 08 46 00 68 30 21 88 43
			10 30 04 49 08 60 08 46 00 68 40 08 40 00 40 1c
			08 60 70 47 00 50 00 40 09 48 40 69 04 21 88 43
			07 49 48 61 08 46 40 69 30 21 88 43 04 49 48 61
			08 46 40 69 40 08 40 00 40 1c 48 61 70 47 00 00
			00 50 00 40 09 48 40 69 02 21 88 43 07 49 48 61
			08 46 40 69 40 08 40 00 48 61 08 46 40 69 04 21
			88 43 00 1d 01 49 48 61 70 47 00 00 00 50 00 40
			00 28 07 d0 07 49 49 69 02 22 91 43 89 1c 05 4a
			51 61 05 e0 03 49 49 69 02 22 91 43 01 4a 51 61
			70 47 00 00 00 50 00 40 09 48 40 68 04 21 88 43
			07 49 48 60 08 46 40 68 30 21 88 43 20 30 04 49
			48 60 08 46 40 68 40 08 40 00 40 1c 48 60 70 47
			00 50 00 40 09 48 40 68 02 21 88 43 07 49 48 60
			08 46 40 68 40 08 40 00 48 60 08 46 40 68 04 21
			88 43 00 1d 01 49 48 60 70 47 00 00 00 50 00 40
			00 28 07 d0 07 49 49 68 02 22 91 43 89 1c 05 4a
			51 60 05 e0 03 49 49 68 02 22 91 43 01 4a 51 60
			70 47 00 00 00 50 00 40 30 b5 03 46 10 48 04 78
			10 48 00 78 98 42 01 dd 0e 48 03 70 0e 48 01 70
			0e 48 02 70 91 42 00 da 0a 46 0a 48 00 78 90 42
			02 dd 07 48 02 70 03 e0 06 48 00 78 04 4d 28 70
			03 48 00 78 84 42 01 d0 05 20 30 bd 00 20 fc e7
			59 00 00 20 5a 00 00 20 32 00 00 20 33 00 00 20
			10 b5 04 46 00 f0 54 fa 00 20 ff f7 37 fc ff f7
			4b ff 20 46 00 f0 6a f8 00 f0 02 f8 10 bd 00 00
			00 bf 04 48 04 49 c8 60 bf f3 4f 8f 00 bf 00 bf
			fe e7 00 00 04 00 fa 05 00 ed 00 e0 10 b5 07 48
			00 78 02 28 09 d0 05 48 00 78 01 28 03 d1 02 20
			02 49 08 70 01 e0 ff f7 e3 ff 10 bd 61 00 00 20
			10 b5 00 24 ff f7 e0 fe 00 bf 0d e0 00 20 ff f7
			f1 fe 01 20 fe f7 e4 ff 01 20 ff f7 eb fe 03 20
			fe f7 de ff 60 1c c4 b2 1e 2c ef db 10 bd 00 00
			07 20 01 21 81 40 0f 4a 11 60 00 bf 0e 48 40 68
			7d 21 c9 01 08 46 0c 49 48 60 08 46 00 68 40 21
			88 43 40 30 08 49 08 60 08 46 00 68 20 21 88 43
			20 30 05 49 08 60 08 46 00 68 40 08 40 00 08 60
			70 47 00 00 00 e1 00 e0 00 10 00 40 02 49 09 68
			c8 07 c0 0f 70 47 00 00 00 10 00 40 fe b5 05 46
			00 27 00 f0 dd f9 01 95 00 20 3e 49 08 70 ff f7
			29 ff fe f7 83 ff 00 20 ff f7 3a ff fe f7 56 ff
			01 20 ff f7 35 ff 00 24 1f e0 37 48 00 78 00 28
			03 d0 58 2d 01 d1 ff f7 bf fe 00 f0 c1 f9 00 bf
			30 48 00 78 00 28 fb d0 00 f0 ba f9 06 20 01 1b
			01 98 08 41 c0 07 c0 0f 00 90 00 98 ff f7 18 ff
			00 20 28 49 08 70 60 1c c4 b2 07 2c dd db 00 f0
			a7 f9 00 24 28 e0 24 48 00 78 00 28 03 d0 58 2d
			01 d1 ff f7 99 fe 00 f0 9b f9 00 bf 1d 48 00 78
			00 28 fb d0 00 f0 94 f9 00 2c 03 d1 ff f7 cc fe
			fe f7 3c ff 00 20 17 49 08 70 ff f7 91 fb 06 46
			06 2c 07 d0 00 2c 05 d0 05 20 01 1b 30 46 88 40
			38 43 c7 b2 60 1c c4 b2 07 2c d4 db 00 f0 78 f9
			00 bf 0c 48 00 78 00 28 fb d0 00 f0 71 f9 ff f7
			c1 fe fe f7 1b ff 00 20 ff f7 d2 fe 00 20 05 49
			08 70 fe f7 eb fe fe f7 e9 fe 00 f0 61 f9 38 46
			fe bd 00 00 11 00 00 20 10 00 00 20 fe b5 05 46
			00 27 00 f0 55 f9 01 95 00 20 3c 49 08 70 ff f7
			a1 fe fe f7 fb fe 00 20 ff f7 b2 fe fe f7 ce fe
			01 20 ff f7 ad fe 00 24 1f e0 35 48 00 78 00 28
			03 d0 58 2d 01 d1 ff f7 37 fe 00 f0 39 f9 00 bf
			2e 48 00 78 00 28 fb d0 00 f0 32 f9 06 20 01 1b
			01 98 08 41 c0 07 c0 0f 00 90 00 98 ff f7 90 fe
			00 20 26 49 08 70 60 1c c4 b2 07 2c dd db 00 f0
			1f f9 00 24 24 e0 22 48 00 78 00 28 03 d0 58 2d
			01 d1 ff f7 11 fe 00 f0 13 f9 00 bf 1b 48 00 78
			00 28 fb d0 00 f0 0c f9 00 2c 03 d1 ff f7 44 fe
			fe f7 b4 fe 00 20 15 49 08 70 ff f7 09 fb 06 46
			06 20 01 1b 30 46 88 40 38 43 c7 b2 60 1c c4 b2
			07 2c d8 db 00 f0 f4 f8 00 bf 0c 48 00 78 00 28
			fb d0 00 f0 ed f8 ff f7 3d fe fe f7 97 fe 00 20
			ff f7 4e fe 00 20 05 49 08 70 fe f7 67 fe fe f7
			65 fe 00 f0 dd f8 38 46 fe bd 00 00 11 00 00 20
			10 00 00 20 00 20 2f 49 08 70 2f 49 08 70 2f 49
			08 70 2f 49 08 70 2f 49 08 70 2f 49 08 70 2f 49
			08 70 2f 49 08 70 2f 49 08 70 01 20 2e 49 08 70
			00 20 48 70 88 70 2d 49 08 70 2d 49 08 70 2d 49
			08 70 2d 49 08 70 03 20 2c 49 08 70 00 20 2c 49
			08 70 2c 49 08 70 2c 49 08 70 2c 49 08 80 40 1e
			2b 49 08 80 00 20 2b 49 08 70 2b 49 08 70 49 20
			2a 49 08 70 2a 49 08 70 00 20 2a 49 08 70 2a 49
			08 70 2a 49 08 70 49 20 29 49 08 70 29 49 08 70
			01 20 29 49 08 70 29 49 08 70 00 20 28 49 08 70
			28 49 08 70 02 20 28 49 08 70 03 20 27 49 08 70
			00 20 27 49 08 70 27 49 08 70 27 49 08 70 27 49
			08 70 70 47 10 00 00 20 17 00 00 20 18 00 00 20
			12 00 00 20 13 00 00 20 14 00 00 20 15 00 00 20
			16 00 00 20 21 00 00 20 70 00 00 20 22 00 00 20
			24 00 00 20 25 00 00 20 26 00 00 20 27 00 00 20
			28 00 00 20 29 00 00 20 2a 00 00 20 2c 00 00 20
			2e 00 00 20 30 00 00 20 31 00 00 20 32 00 00 20
			33 00 00 20 34 00 00 20 37 00 00 20 58 00 00 20
			59 00 00 20 5a 00 00 20 5b 00 00 20 5c 00 00 20
			5d 00 00 20 5e 00 00 20 5f 00 00 20 60 00 00 20
			61 00 00 20 66 00 00 20 0a 00 00 20 0b 00 00 20
			f3 b5 81 b0 0d 46 00 24 00 26 00 27 00 20 00 90
			01 98 fe f7 23 fc 04 46 28 46 fe f7 1f fc 06 46
			a4 1b 7d 27 ff 00 78 00 00 90 bc 42 01 da 00 20
			fe bd 00 98 84 42 01 dd 02 20 f9 e7 01 20 f7 e7
			5a 20 02 49 08 61 80 20 08 61 70 47 00 70 00 40
			5a 20 05 49 08 61 08 46 00 69 40 21 88 43 40 30
			01 49 08 61 70 47 00 00 00 70 00 40 00 00 00 01
			01 01 00 01 00 00 01 01 01 00 00 00 00 01 00 01
			00 01 01 00 00 01 01 00 00 00 01 00 01 00 00 01
			00 00 01 01 01 00 00 00 00 01 00 01 00 01 01 00
			00 01 01 00 00 01 00 01 00 00 00 01 00 00 01 01
			01 00 00 00 01 01 01 00 00 01 01 00 01 00 00 01
			00 00 00 01 00 01 00 01 01 00 01 01 00 00 00 01
			01 01 01 00 00 01 00 00 01 00 00 01 00 01 00 01
			00 01 00 01 00 01 00 00 01 00 00 01 00 00 00 00
			00 01 01 00 01 00 00 01 00 00 00 01 00 01 00 01
			01 00 01 01 00 00 00 01 01 01 01 00 00 01 00 00
			01 00 00 01 00 01 00 01 00 01 00 01 00 01 00 00
			01 00 00 01 00 00 00 00 00 01 01 00 01 00 00 01
			00 00 00 01 01 00 00 01 01 00 01 01 00 00 00 00
			00 01 00 01 01 01 01 00 01 01 00 00 00 00 00 00
			00 00 00 00 00 00 00 00 00 00 00 00 00 00 00 00
			00 00 00 00 00 00 00 00 00 00 00 00 00 00 00 00
			00 00 00 00 00 00 00 00 38 2d 00 00 00 00 00 20
			70 00 00 00 d0 00 00 00 a8 2d 00 00 70 00 00 20
			78 05 00 00 ec 00 00 00 00 00 00 00 00 00 00 00
			00 00 00 00 00 00 00 00 00 00 00 00 00 00 00 00
			00 00 00 00 00 00 00 00 00 00 00 00 00 00 00 00
			00 00 00 00 00 00 00 00 00 00 00 00 00 00 00 00
			00 00 00 00 00 00 00 00 00 00 00 00 00 00 00 00
			00 00 00 00 00 00 00 00 00 00 00 00 00 00 00 00
			00 00 00 00 00 00 00 00 00 00 00 00 00 00 00 00
			00 00 00 00 00 00 00 00 00 02 01 08 08 01 05 fe
			d2 34 55 34];
	};

	sy6610_fastcg@06{
		status = "okay";
		compatible = "oplus,sy6610-fastcg";
		reg = <0x06 0>;
		qcom,vooc-low-temp = <0>;
		qcom,oplus_batt_4250mv;
		qcom,vooc-high-soc = <90>;
		qcom,vooc-low-soc = <1>;
		qcom,vooc_reply_mcu_bits = <7>;
		qcom,vooc_fw_update_newmethod;
		qcom,vooc-high-temp = <430>;
		qcom,vooc-fw-type = <5>;
		qcom,support-single-batt-svooc;
		qcom,support_vooc_by_normal_charger_path;

		qcom,vooc-little-cool-temp = <160>;
		qcom,vooc-cool-temp = <120>;
		qcom,vooc-little-cool-to-normal-temp = <180>;
		qcom,vooc-normal-to-little-cool-current = <0x05>;//5A

		qcom,vooc_cool_bat_volt = <3450>;
		qcom,vooc_little_cool_bat_volt = <3400>;
		qcom,vooc_normal_bat_volt = <3350>;
		qcom,vooc_warm_bat_volt = <3300>;

		qcom,vooc_cool_bat_suspend_volt = <3450>;
		qcom,vooc_little_cool_bat_suspend_volt = <3400>;
		qcom,vooc_normal_bat_suspend_volt = <3350>;
		qcom,vooc_warm_bat_suspend_volt = <3300>;

		qcom,vooc_multistep_adjust_current_support;
		qcom,vooc_multistep_initial_batt_temp = <1000>;
		qcom,vooc_strategy_normal_current = <0x0c>;

		qcom,vooc_batt_over_high_temp = <440>;
		qcom,vooc_batt_over_low_temp = <45>;
		qcom,vooc_over_high_or_low_current = <0x0>;

		qcom,vooc_strategy1_batt_high_temp0 = <400>;
		qcom,vooc_strategy1_batt_high_temp1 = <420>;
		qcom,vooc_strategy1_batt_high_temp2 = <430>;
		qcom,vooc_strategy1_batt_low_temp2 = <420>;
		qcom,vooc_strategy1_batt_low_temp1 = <410>;
		qcom,vooc_strategy1_batt_low_temp0 = <390>;

		qcom,vooc_strategy1_high_current0 = <0x09>;  // 5A
		qcom,vooc_strategy1_high_current1 = <0x07>;  // 4A
		qcom,vooc_strategy1_high_current2 = <0x05>;  // 3A
		qcom,vooc_strategy1_low_current2 = <0x07>;   // 4A
		qcom,vooc_strategy1_low_current1 = <0x09>;   // 5A
		qcom,vooc_strategy1_low_current0 = <0x0c>;

		qcom,vooc_strategy2_batt_up_temp1 = <375>;
		qcom,vooc_strategy2_batt_up_down_temp2 = <380>;
		qcom,vooc_strategy2_batt_up_temp3 = <390>;
		qcom,vooc_strategy2_batt_up_down_temp4 = <400>;
		qcom,vooc_strategy2_batt_up_temp5 = <410>;
		qcom,vooc_strategy2_batt_up_temp6 = <415>;
		qcom,vooc_strategy2_high0_current = <0x09>;
		qcom,vooc_strategy2_high1_current = <0x07>;
		qcom,vooc_strategy2_high2_current = <0x05>;
		qcom,vooc_strategy2_high3_current = <0x03>;
		qcom,abnormal_adapter_current = <0x00 0x00 0x09 0x09 0x07 0x07 0x05 0x05 0x03 0x03>;
		qcom,vooc_current_lvl = <1000
									1500
									2000
									2500
									3000
									3500
									4000
									4500
									5000
									5500
									6000
									6500
									7000
									7500
									8000
									8500
									9000
									9500
									10000
									10500
									11000
									11500
									12000
									12500>;
		pinctrl-names = "switch1_act_switch2_act", "switch1_sleep_switch2_sleep",
						"switch1_act_switch3_act", "switch1_sleep_switch3_sleep",
						"switch1_act_switch2_sleep", "switch1_sleep_switch2_act",
						"clock_active","clock_sleep",
						"data_active","data_sleep",
						"reset_active","reset_sleep",
						"vooc_asic_id_active","vooc_asic_id_sleep";
		pinctrl-0 = <&charging_switch1_active>;
		pinctrl-1 = <&charging_switch1_sleep>;
		pinctrl-2 = <&charging_switch1_active>;
		pinctrl-3 = <&charging_switch1_sleep>;
		pinctrl-4 = <&charging_switch1_active>;
		pinctrl-5 = <&charging_switch1_sleep>;
		pinctrl-6 = <&charging_clock_active>;
		pinctrl-7 = <&charging_clock_sleep>;
		pinctrl-8 = <&charging_data_active>;
		pinctrl-9 = <&charging_data_sleep>;
		pinctrl-10 = <&charging_reset_active>;
		pinctrl-11 = <&charging_reset_sleep>;
		pinctrl-12 = <&vooc_asic_id_active>;
		pinctrl-13 = <&vooc_asic_id_sleep>;

		qcom,charging_switch1-gpio 		= <&pio 191 0x00>;              //SW_CTRL
		//qcom,charging_switch1_ctr1-gpio 	= <&pio 148 0x00>;

		qcom,charging_reset-gpio 			= <&pio 189 0x00>;//MCU_EN
		qcom,charging_clock-gpio 			= <&pio 95 0x00>;//AP_CLK
		qcom,charging_data-gpio 			= <&pio 94 0x00>;//AP_DATA
		qcom,vooc_asic_id-gpio				= <&pio 187 0x00>;
		qcom,supported_hiz_gnd_cable;
		qcom,parse_fw_from_dt;
		vooc,firmware_data = [
			20 05 00 20 d5 00 00 00 cb 02 00 00 f5 01 00 00
			00 00 00 00 00 00 00 00 00 00 00 00 00 00 00 00
			00 00 00 00 00 00 00 00 00 00 00 00 e1 00 00 00
			00 00 00 00 00 00 00 00 e3 00 00 00 cd 03 00 00
			e7 00 00 00 e9 00 00 00 eb 00 00 00 ed 00 00 00
			ef 00 00 00 f1 00 00 00 f3 00 00 00 f5 00 00 00
			61 23 00 00 75 23 00 00 fb 00 00 00 fd 00 00 00
			ff 00 00 00 01 01 00 00 03 01 00 00 11 2c 00 00
			07 01 00 00 ad 1e 00 00 19 24 00 00 d5 2d 00 00
			0f 01 00 00 11 01 00 00 13 01 00 00 15 01 00 00
			17 01 00 00 19 01 00 00 1d 01 00 00 1d 01 00 00
			1f 01 00 00 21 01 00 00 23 01 00 00 25 01 00 00
			03 48 85 46 00 f0 84 f8 00 48 00 47 e1 24 00 00
			20 05 00 20 14 48 80 47 14 48 00 47 fe e7 fe e7
			fe e7 fe e7 fe e7 fe e7 fe e7 fe e7 fe e7 fe e7
			fe e7 fe e7 fe e7 fe e7 fe e7 fe e7 fe e7 fe e7
			fe e7 fe e7 fe e7 fe e7 fe e7 fe e7 fe e7 fe e7
			fe e7 fe e7 fe e7 fe e7 fe e7 fe e7 fe e7 fe e7
			fe e7 fe e7 fe e7 00 00 e5 03 00 00 c1 00 00 00
			30 b5 0b 46 01 46 00 20 20 22 01 24 09 e0 0d 46
			d5 40 9d 42 05 d3 1d 46 95 40 49 1b 25 46 95 40
			40 19 15 46 52 1e 00 2d f1 dc 30 bd 70 b5 00 24
			25 46 00 28 01 da 01 24 40 42 00 29 01 da 01 25
			49 42 ff f7 dd ff ac 42 00 d0 40 42 00 2c 00 d0
			49 42 70 bd d2 b2 01 e0 02 70 40 1c 49 1e fb d2
			70 47 00 22 f6 e7 10 b5 13 46 0a 46 04 46 19 46
			ff f7 f0 ff 20 46 10 bd 03 21 00 1d 40 1e 03 78
			12 02 1a 43 49 1e f9 d5 10 46 70 47 03 46 03 22
			08 70 00 0a 49 1c 52 1e fa d5 18 46 70 47 00 00
			06 4c 01 25 06 4e 05 e0 e3 68 07 cc 2b 43 0c 3c
			98 47 10 34 b4 42 f7 d3 ff f7 6e ff d4 33 00 00
			f4 33 00 00 04 20 71 46 08 42 02 d1 ef f3 08 80
			01 e0 ef f3 09 80 00 00 00 4a 10 47 8d 02 00 00
			00 20 03 49 09 68 01 22 12 03 11 40 08 0b 70 47
			00 00 01 40 10 b5 01 f0 93 fe 04 46 10 20 20 40
			00 28 17 d0 04 20 01 f0 55 fe 10 48 00 68 00 28
			07 d1 02 f0 45 fe 00 20 0d 49 08 70 01 20 0b 49
			08 60 0c 48 00 78 02 28 02 d1 00 f0 45 fc 01 e0
			00 f0 dc ff 01 20 80 02 20 40 00 28 05 d0 0a 20
			01 f0 38 fe 01 20 04 49 08 70 10 bd a0 00 00 20
			62 00 00 20 8b 00 00 20 3d 00 00 20 00 bf fe e7
			f8 b5 04 46 0d 46 16 46 33 46 2a 46 21 46 55 20
			01 f0 78 fe 07 46 38 46 f8 bd f8 b5 05 46 14 46
			20 78 61 78 09 02 08 43 06 46 32 46 29 46 55 20
			01 f0 64 ff 07 46 38 46 f8 bd 70 47 00 bf 72 b6
			00 bf 05 48 00 69 01 21 09 03 88 43 02 49 08 61
			00 bf 62 b6 00 bf 70 47 00 00 01 40 06 48 40 68
			01 21 09 03 88 43 04 49 48 60 08 46 00 69 89 14
			08 43 01 49 08 61 70 47 00 00 01 40 00 bf 72 b6
			00 bf 05 48 00 69 01 21 09 03 88 43 02 49 08 61
			00 bf 62 b6 00 bf 70 47 00 00 01 40 03 48 00 69
			01 21 09 03 88 43 01 49 08 61 70 47 00 00 01 40
			00 bf 72 b6 00 bf 05 48 00 69 01 21 c9 02 88 43
			02 49 08 61 00 bf 62 b6 00 bf 70 47 00 00 01 40
			00 bf 72 b6 00 bf 08 48 40 68 01 21 c9 02 88 43
			05 49 48 60 08 46 00 69 c9 14 08 43 02 49 08 61
			00 bf 62 b6 00 bf 70 47 00 00 01 40 06 48 40 68
			01 21 c9 02 88 43 04 49 48 60 08 46 00 69 c9 14
			08 43 01 49 08 61 70 47 00 00 01 40 00 bf 72 b6
			00 bf 05 48 00 69 01 21 c9 02 88 43 02 49 08 61
			00 bf 62 b6 00 bf 70 47 00 00 01 40 04 48 00 68
			00 28 04 d0 02 48 00 68 40 1e 01 49 08 60 70 47
			ac 00 00 20 70 47 00 00 10 b5 37 48 00 88 00 28
			05 d0 35 48 00 88 40 1e 33 49 08 80 15 e0 7d 20
			c0 00 31 49 08 80 31 48 00 88 00 28 04 d0 2f 48
			00 88 40 1e 2d 49 08 80 2d 48 00 88 00 28 04 d0
			2b 48 00 88 40 1e 2a 49 08 80 2a 48 00 68 00 28
			04 d0 28 48 00 68 40 1e 26 49 08 60 26 48 00 68
			00 28 04 d0 24 48 00 68 40 1e 23 49 08 60 23 48
			00 68 00 28 04 d0 21 48 00 68 40 1e 1f 49 08 60
			1f 48 00 78 00 28 04 d0 1d 48 00 78 40 1e 1c 49
			08 70 1c 48 00 68 00 28 04 d0 1a 48 00 68 40 1e
			18 49 08 60 18 48 00 68 00 28 04 d0 16 48 00 68
			40 1e 15 49 08 60 15 48 00 78 40 1c 13 49 08 70
			08 46 00 78 c8 28 0e dd 00 20 08 70 10 48 00 78
			00 28 05 d0 00 20 01 f0 71 fc 01 20 0d 49 08 70
			01 20 0b 49 08 70 10 bd 64 00 00 20 66 00 00 20
			68 00 00 20 6c 00 00 20 70 00 00 20 74 00 00 20
			78 00 00 20 7c 00 00 20 80 00 00 20 62 00 00 20
			4f 00 00 20 3c 00 00 20 30 b4 74 46 64 1e 25 78
			64 1c ab 42 04 d3 63 5d 5b 00 e3 18 30 bc 18 47
			1d 46 f8 e7 00 28 05 db c2 06 d2 0e 01 21 91 40
			01 4a 11 60 70 47 00 00 00 e1 00 e0 10 b5 00 28
			19 db 1a 4a 03 23 1b 02 d2 18 83 08 9b 00 d2 58
			83 07 dc 0e ff 23 a3 40 9a 43 8b 07 1b 0e 84 07
			e4 0e a3 40 1a 43 11 4b 03 24 24 02 1b 19 84 08
			a4 00 1a 51 18 e0 0e 4a 03 07 1b 0f 08 3b 9b 08
			9b 00 d2 58 83 07 dc 0e ff 23 a3 40 9a 43 8b 07
			1b 0e 84 07 e4 0e a3 40 1a 43 05 4b 04 07 24 0f
			08 3c a4 08 a4 00 1a 51 10 bd 00 00 00 e1 00 e0
			1c ed 00 e0 10 b5 00 28 19 db 1a 4a 03 23 1b 02
			d2 18 83 08 9b 00 d2 58 83 07 dc 0e ff 23 a3 40
			9a 43 8b 07 1b 0e 84 07 e4 0e a3 40 1a 43 11 4b
			03 24 24 02 1b 19 84 08 a4 00 1a 51 18 e0 0e 4a
			03 07 1b 0f 08 3b 9b 08 9b 00 d2 58 83 07 dc 0e
			ff 23 a3 40 9a 43 8b 07 1b 0e 84 07 e4 0e a3 40
			1a 43 05 4b 04 07 24 0f 08 3c a4 08 a4 00 1a 51
			10 bd 00 00 00 e1 00 e0 1c ed 00 e0 02 e0 08 c8
			12 1f 08 c1 00 2a fa d1 70 47 70 47 00 20 01 e0
			01 c1 12 1f 00 2a fb d1 70 47 00 00 30 b5 42 68
			0d 4c d5 02 23 46 10 33 e2 68 00 2d 09 da d3 5c
			43 67 52 1c e2 60 03 22 0a 70 01 21 61 70 89 1e
			07 e0 05 6f d5 54 e2 68 52 1c e2 60 04 22 0a 70
			11 04 41 60 00 20 30 bd f0 00 00 20 10 b5 42 68
			12 03 0a d5 08 4c 23 46 e2 68 10 33 d3 5c 43 67
			52 1c e2 60 01 22 d2 04 42 60 40 68 c0 01 01 d5
			05 20 08 70 00 20 10 bd f0 00 00 20 70 b5 42 68
			05 24 52 03 00 2a 16 da 0e 4b da 68 04 2a 0a d2
			05 6f 1e 46 10 36 95 55 da 68 52 1c da 60 01 22
			92 04 42 60 07 e0 08 4a 55 6f 96 15 35 43 55 67
			0c 70 02 22 5a 70 40 68 c0 01 00 d5 0c 70 00 20
			70 bd 00 00 f0 00 00 20 00 c0 00 40 70 b5 42 68
			0d 4b 0e 4c 52 03 08 d5 05 6f 62 68 9e 18 35 72
			52 1c 62 60 01 22 92 04 42 60 58 68 62 68 90 42
			07 d1 02 20 08 70 00 20 60 60 05 49 18 69 40 18
			18 61 00 20 70 bd 00 00 f0 00 00 20 0c 00 00 20
			02 02 02 02 42 68 d2 02 03 d5 00 21 c9 43 41 60
			07 e0 42 68 52 03 06 d5 01 22 92 04 42 60 01 20
			08 70 00 20 70 47 01 20 70 47 00 00 00 b5 40 68
			0b 46 c0 01 06 d5 01 f0 71 fe 00 20 02 49 18 70
			48 70 c8 60 02 20 00 bd f0 00 00 20 f8 b5 05 46
			0f 46 ff f7 0b fe 07 26 3c e0 00 24 00 bf 72 b6
			00 bf ff f7 c3 fd 09 e0 4b 20 80 01 84 42 04 d3
			ff f7 fc fd ff f7 aa fd f8 bd 64 1c ff f7 28 fd
			00 28 f1 d0 00 bf 00 20 2f 49 09 68 01 22 d2 02
			11 40 c8 0a 00 bf b0 40 29 78 08 43 28 70 ff f7
			85 fd 00 bf 62 b6 00 bf 00 bf 00 bf 00 bf 00 bf
			00 bf 00 bf 00 bf 00 bf 00 bf 00 bf 00 bf 00 bf
			00 bf 00 bf 00 bf 00 bf 00 bf 00 bf 00 bf 00 bf
			00 bf 76 1e 00 2e c0 da 00 2f 02 d0 ff f7 90 fd
			11 e0 ff f7 9d fd 00 bf 00 bf 00 bf 72 b6 00 bf
			15 48 00 69 01 21 c9 02 08 43 13 49 08 61 00 bf
			62 b6 00 bf 00 bf 00 f0 fd fe 00 24 00 bf 72 b6
			00 bf ff f7 6b fd 09 e0 4b 20 80 01 84 42 04 d3
			ff f7 a4 fd ff f7 52 fd a6 e7 64 1c ff f7 d0 fc
			00 28 f1 d0 ff f7 3a fd 00 bf 62 b6 00 bf 00 f0
			e1 fe 00 bf 98 e7 00 00 00 00 01 40 f8 b5 07 46
			00 f0 c8 fe 07 25 33 e0 00 bf 72 b6 00 bf 01 20
			a8 40 38 40 00 28 09 d0 00 bf 32 48 00 69 01 21
			c9 02 88 43 2f 49 08 61 00 bf 01 e0 ff f7 66 fd
			00 24 00 bf 2b 48 00 69 01 21 09 03 88 43 29 49
			08 61 00 bf 0a e0 4b 20 80 01 84 42 05 d3 ff f7
			65 fd ff f7 13 fd 01 20 f8 bd 64 1c ff f7 90 fc
			00 28 f0 d0 ff f7 fa fc 00 bf 62 b6 00 bf 6d 1e
			00 2d c9 da ff f7 52 fd 00 bf 00 bf 00 bf 00 bf
			00 bf 00 bf 00 bf 00 bf 00 bf 00 bf 00 bf 00 bf
			00 f0 90 fe 00 24 00 bf 72 b6 00 bf ff f7 fe fc
			0a e0 4b 20 80 01 84 42 05 d3 ff f7 37 fd ff f7
			e5 fc 01 20 d0 e7 64 1c ff f7 62 fc 00 28 f0 d0
			00 bf 01 20 07 49 09 68 c2 02 11 40 c8 0a 00 bf
			06 46 ff f7 c3 fc 00 bf 62 b6 00 bf 00 f0 6a fe
			30 46 b9 e7 00 00 01 40 10 b5 ff f7 a7 fc 00 bf
			00 bf 00 bf 00 bf 00 bf 00 bf 00 bf 00 bf 00 bf
			00 bf 00 bf 00 bf 00 bf 00 bf 00 bf 00 bf 00 bf
			00 bf 00 bf 00 bf 00 bf 72 b6 00 bf ff f7 ee fc
			00 bf 00 bf 00 bf 00 bf 00 bf 00 bf 00 bf 00 bf
			00 bf 00 bf 00 bf 00 bf ff f7 90 fc 00 bf 62 b6
			00 bf 10 bd 10 b5 00 bf 72 b6 00 bf ff f7 d6 fc
			00 bf 00 bf 00 bf 00 bf 00 bf 00 bf 00 bf 00 bf
			00 bf 00 bf 00 bf ff f7 79 fc 00 bf 62 b6 00 bf
			10 bd 00 00 10 b5 00 24 ff f7 aa fc 00 bf 00 bf
			00 bf 00 bf 00 bf 00 bf 00 bf 00 bf 00 bf 00 bf
			00 bf 00 bf ff f7 52 fc 09 e0 4b 20 80 01 84 42
			04 d3 ff f7 bb fc ff f7 69 fc 10 bd 64 1c 00 bf
			00 20 00 bf 00 bf 72 b6 00 bf 12 49 09 68 01 22
			12 03 11 40 08 0b 00 bf 62 b6 00 bf 00 28 e4 d0
			00 bf 00 bf 00 bf 00 bf 00 bf 00 bf 00 bf 00 bf
			00 bf 00 bf 00 bf 00 bf 00 bf 00 bf 00 bf 00 bf
			00 bf 00 bf 00 bf 00 bf 00 bf ff f7 59 fc 00 bf
			d3 e7 00 00 00 00 01 40 10 b5 00 20 11 49 89 69
			03 22 12 02 91 43 02 02 03 23 1b 02 1a 40 11 43
			0c 4a 91 61 00 bf 02 21 04 20 01 f0 fd fb 00 20
			08 49 89 69 03 22 92 02 91 43 82 02 03 23 9b 02
			1a 40 11 43 03 4a 91 61 00 bf 02 21 05 20 01 f0
			eb fb 10 bd 00 00 01 40 10 b5 f7 48 00 78 08 28
			0b da 01 f0 97 f9 f5 49 f3 4a 12 78 88 54 f2 48
			00 78 40 1c f0 49 08 70 10 bd ef 48 00 78 08 28
			29 d1 09 20 ec 49 08 70 02 f0 fa f8 eb 48 00 78
			01 28 21 d1 e9 48 40 78 00 28 1d d1 e7 48 80 78
			01 28 19 d1 e5 48 c0 78 c0 00 e4 49 09 79 89 00
			08 43 e2 49 49 79 49 00 08 43 e0 49 89 79 08 43
			df 49 08 70 00 20 df 49 08 70 df 48 00 78 00 28
			d6 d1 de 49 08 70 96 e0 d8 48 00 78 01 28 20 d1
			d6 48 40 78 00 28 1c d1 d4 48 80 78 00 28 18 d1
			d2 48 c0 78 c0 00 d1 49 09 79 89 00 08 43 cf 49
			49 79 49 00 08 43 cd 49 89 79 08 43 cc 49 08 70
			00 20 cc 49 08 70 cc 49 08 70 02 20 cb 49 08 70
			71 e0 c6 48 40 78 01 28 21 d1 c4 48 80 78 00 28
			1d d1 c2 48 c0 78 01 28 19 d1 c0 48 00 79 c0 00
			be 49 49 79 89 00 08 43 bc 49 89 79 49 00 08 43
			ba 49 c9 79 08 43 ba 49 08 70 00 20 b9 49 08 70
			b9 48 00 78 00 28 01 d1 b8 49 08 70 84 e7 b3 48
			40 78 01 28 20 d1 b1 48 80 78 00 28 1c d1 af 48
			c0 78 00 28 18 d1 ad 48 00 79 c0 00 ab 49 49 79
			89 00 08 43 a9 49 89 79 49 00 08 43 a7 49 c9 79
			08 43 a7 49 08 70 00 20 a6 49 08 70 a6 49 08 70
			02 20 a6 49 08 70 5f e7 a0 48 c0 78 c0 00 9f 49
			09 79 89 00 08 43 9d 49 49 79 49 00 08 43 9b 49
			89 79 08 43 9a 49 08 70 00 20 9b 49 08 70 02 20
			9a 49 08 70 9a 48 00 78 01 28 09 d1 95 48 00 78
			00 28 05 d1 93 48 00 78 40 1c 92 49 08 70 02 e0
			01 20 94 49 08 70 94 48 00 78 00 28 14 d1 93 49
			c8 70 08 71 48 71 88 71 c8 71 08 72 48 72 90 48
			00 78 02 28 09 d1 86 48 00 78 00 07 00 0e 8d 49
			08 70 01 20 89 49 48 71 12 e2 89 48 00 78 01 28
			0a d1 88 48 00 78 7e 49 09 78 08 43 85 49 08 70
			01 20 82 49 48 71 03 e2 83 48 00 78 05 28 16 d1
			7e 48 80 7a 7d 49 c8 70 08 46 c0 7a 08 71 08 46
			00 7b 48 71 08 46 40 7b 88 71 08 46 80 7b c8 71
			08 46 c0 7b 08 72 08 46 00 7c 48 72 e8 e1 76 48
			00 78 04 28 09 d1 6a 48 00 78 00 07 00 0c 73 49
			08 80 01 20 6d 49 48 71 da e1 6f 48 00 78 03 28
			0b d1 63 48 00 78 00 02 6c 49 09 88 08 43 6b 49
			08 80 01 20 65 49 48 71 ca e1 67 48 00 78 02 28
			0b d1 5b 48 00 78 00 01 64 49 09 88 08 43 63 49
			08 80 01 20 5d 49 48 71 ba e1 5f 48 00 78 01 28
			15 d1 5e 48 00 88 52 49 09 78 08 43 5b 49 08 80
			00 f0 6e fb 01 20 55 49 48 71 59 48 00 88 57 49
			09 88 88 42 90 d1 01 20 56 49 08 70 a0 e1 56 48
			00 78 00 28 4c d0 54 48 00 78 40 1e c1 00 08 1a
			52 49 09 68 08 5c 49 49 c8 70 4f 48 00 78 40 1e
			c1 00 08 1a 4d 49 09 68 40 18 40 78 43 49 08 71
			49 48 00 78 40 1e c1 00 08 1a 48 49 09 68 40 18
			80 78 3e 49 48 71 44 48 00 78 40 1e c1 00 08 1a
			42 49 09 68 40 18 c0 78 38 49 88 71 3e 48 00 78
			40 1e c1 00 08 1a 3d 49 09 68 40 18 00 79 33 49
			c8 71 39 48 00 78 40 1e c1 00 08 1a 37 49 09 68
			40 18 40 79 2d 49 08 72 33 48 00 78 40 1e c1 00
			08 1a 32 49 09 68 40 18 80 79 28 49 48 72 4f e1
			1f 48 00 78 09 28 0c d1 00 20 25 49 08 70 26 49
			08 70 29 49 08 70 00 f0 99 ff 01 20 28 49 08 70
			4a e6 00 20 1e 49 08 70 1f 49 08 70 22 49 08 70
			13 48 00 78 03 00 ff f7 37 fb 10 09 0d 8d a7 da
			f2 53 53 53 53 53 53 fa ef ee ed 53 01 20 1d 49
			08 70 31 e6 01 20 0e 49 08 70 1b 48 00 78 00 28
			3f d0 1a 48 00 78 00 28 32 d1 01 20 0b 49 c8 70
			08 71 08 72 48 72 2e e0 4c 00 00 20 44 00 00 20
			4e 00 00 20 41 00 00 20 8c 00 00 20 8b 00 00 20
			40 00 00 20 3e 00 00 20 4d 00 00 20 04 01 00 20
			50 00 00 20 51 00 00 20 53 00 00 20 56 00 00 20
			58 00 00 20 5a 00 00 20 54 00 00 20 2c 00 00 20
			43 00 00 20 3f 00 00 20 61 00 00 20 8a 00 00 20
			01 20 a1 49 88 71 a1 48 00 78 c0 43 9f 49 08 70
			dd e0 9f 48 00 78 00 28 0e d0 01 20 9a 49 c8 70
			08 71 48 71 88 71 c8 71 08 72 48 72 98 48 00 78
			40 1e 97 49 08 70 ca e0 96 48 00 68 96 49 88 42
			01 da 00 24 07 e0 93 49 09 68 93 4a 88 1a 0a 21
			ff f7 f4 f8 04 46 60 06 c0 0f 8b 49 c8 70 a0 06
			c0 0f 08 71 e0 06 c0 0f 48 71 20 07 c0 0f 88 71
			60 07 c0 0f c8 71 a0 07 c0 0f 08 72 e0 07 c0 0f
			48 72 a4 e0 00 21 08 46 02 f0 50 f9 83 49 08 70
			08 46 00 78 02 28 03 d1 01 20 7b 49 08 71 0a e0
			7e 48 00 78 01 28 03 d1 77 49 08 71 48 71 02 e0
			01 20 75 49 48 71 8a e0 79 48 00 78 40 06 c0 0f
			71 49 c8 70 76 48 00 78 80 06 c0 0f 08 71 74 48
			00 78 c0 06 c0 0f 48 71 71 48 00 78 00 07 c0 0f
			88 71 6f 48 00 78 40 07 c0 0f c8 71 6c 48 00 78
			80 07 c0 0f 08 72 6a 48 00 78 c0 07 c0 0f 48 72
			00 20 63 49 08 70 66 48 00 78 64 21 48 43 ff 30
			2d 30 64 49 08 80 0a 20 63 49 08 70 57 e0 63 48
			00 78 00 28 07 d0 00 20 61 49 08 70 5f 48 00 78
			40 1e 5e 49 08 70 5e 48 00 78 53 49 c8 70 01 20
			48 71 44 e0 3f e0 3a e0 21 e0 08 e0 ff e7 03 20
			58 49 08 70 01 20 4c 49 08 71 88 71 37 e0 56 48
			00 78 00 28 03 d0 55 48 00 78 00 28 00 d1 2e e0
			51 48 00 78 40 1e 50 49 08 70 06 20 50 49 08 70
			00 f0 df fe 4f 49 08 70 00 f0 88 f9 1f e0 4e 48
			00 78 40 1c 4d 49 08 70 4b 48 00 78 80 1c 4c 49
			08 70 4c 48 00 78 38 49 c8 70 4b 48 00 78 08 71
			4a 48 00 78 48 71 4a 48 00 78 88 71 07 e0 01 20
			48 49 08 70 10 e5 01 20 46 49 08 70 0c e5 00 bf
			2d 49 45 4a 12 78 88 5c 01 f0 14 fe 42 48 00 78
			40 1c 41 49 08 70 08 46 00 78 09 28 49 dd 04 20
			00 f0 c0 fa 01 f0 f6 fd 00 20 3b 49 08 70 3b 49
			08 70 3b 49 08 70 2b 48 00 78 00 28 05 d0 29 48
			00 78 40 1e 27 49 08 70 33 e0 29 48 00 78 00 28
			05 d0 27 48 00 78 40 1e 25 49 08 70 29 e0 27 48
			00 78 00 28 0a d0 25 48 00 78 40 1e 23 49 08 70
			23 48 00 78 40 1e 22 49 08 70 1a e0 29 48 00 78
			02 28 02 d0 04 28 13 d1 0a e0 10 48 00 78 01 28
			05 d1 13 48 00 78 01 28 01 d1 00 f0 07 fe 07 e0
			01 20 12 49 08 70 00 f0 64 fe 1f 49 08 70 00 bf
			00 bf 00 bf b0 e4 00 00 04 01 00 20 8a 00 00 20
			84 00 00 20 38 00 00 20 4c 0d 00 00 98 00 00 20
			85 00 00 20 8e 00 00 20 90 00 00 20 8c 00 00 20
			42 00 00 20 50 00 00 20 52 00 00 20 5e 00 00 20
			53 00 00 20 60 00 00 20 30 00 00 20 54 00 00 20
			55 00 00 20 32 00 00 20 33 00 00 20 34 00 00 20
			35 00 00 20 3f 00 00 20 4d 00 00 20 4c 00 00 20
			4f 00 00 20 4e 00 00 20 5f 00 00 20 10 b5 5d 48
			00 78 08 28 0b da 00 f0 fd fd 5b 49 59 4a 12 78
			88 54 58 48 00 78 40 1c 56 49 08 70 10 bd 55 48
			00 78 08 28 61 d1 09 20 52 49 08 70 01 f0 60 fd
			51 48 00 78 01 28 1b d1 4f 48 40 78 00 28 17 d1
			4d 48 80 78 01 28 13 d1 4b 48 c0 78 c0 00 4a 49
			09 79 89 00 08 43 48 49 49 79 49 00 08 43 46 49
			89 79 08 43 45 49 08 70 00 20 45 49 08 70 3c e0
			41 48 40 78 01 28 1b d1 3f 48 80 78 00 28 17 d1
			3d 48 c0 78 01 28 13 d1 3b 48 00 79 c0 00 3a 49
			49 79 89 00 08 43 38 49 89 79 49 00 08 43 36 49
			c9 79 08 43 35 49 08 70 00 20 35 49 08 70 b5 e7
			31 48 c0 78 c0 00 30 49 09 79 89 00 08 43 2e 49
			49 79 49 00 08 43 2c 49 89 79 08 43 2b 49 08 70
			2b 48 00 78 00 28 05 d1 29 48 00 78 40 1c 28 49
			08 70 02 e0 01 20 27 49 08 70 27 48 00 78 00 28
			22 d1 01 20 25 49 88 70 00 20 c8 70 08 71 48 71
			88 71 c8 71 08 72 48 72 1c 48 00 78 04 28 02 d0
			06 28 0c d1 07 e0 1e 48 00 78 1c 49 c8 70 01 20
			c8 71 48 72 07 e0 01 20 18 49 c8 70 03 e0 01 20
			18 49 08 70 72 e7 00 bf 14 49 13 4a 12 78 88 5c
			01 f0 e0 fc 10 48 00 78 40 1c 0f 49 08 70 08 46
			00 78 09 28 0b dd 04 20 00 f0 8c f9 01 f0 c2 fc
			00 20 09 49 08 70 03 49 08 70 0b 49 08 70 00 bf
			54 e7 00 00 4c 00 00 20 44 00 00 20 4e 00 00 20
			41 00 00 20 3e 00 00 20 4d 00 00 20 04 01 00 20
			42 00 00 20 3f 00 00 20 4f 00 00 20 28 48 00 78
			40 02 28 49 09 78 49 00 08 43 27 49 08 80 24 48
			00 78 40 06 c0 0f 25 49 48 71 21 48 00 78 80 06
			c0 0f c8 72 1e 48 00 78 c0 06 c0 0f 08 72 1c 48
			00 78 00 07 c0 0f 08 74 19 48 00 78 40 07 c0 0f
			88 73 17 48 00 78 80 07 c0 0f 48 73 14 48 00 78
			c0 07 c0 0f c8 71 13 48 00 78 40 06 c0 0f c8 70
			10 48 00 78 80 06 c0 0f 08 73 0e 48 00 78 c0 06
			c0 0f 08 71 0b 48 00 78 00 07 c0 0f 88 72 09 48
			00 78 40 07 c0 0f 48 72 06 48 00 78 80 07 c0 0f
			c8 73 04 48 00 78 c0 07 c0 0f 88 71 70 47 00 00
			5f 00 00 20 60 00 00 20 58 00 00 20 04 01 00 20
			03 48 00 88 03 49 08 40 01 49 08 80 70 47 00 00
			56 00 00 20 fe fe 00 00 10 b5 04 46 01 f0 aa fb
			20 46 01 f0 cd fb 80 b2 10 bd 70 47 70 47 00 00
			f8 b5 05 46 00 26 0d e0 6a 46 02 21 28 46 fe f7
			ef fe 00 28 00 d1 07 e0 00 f0 c4 f8 00 20 00 90
			70 1c c6 b2 03 2e ef db 00 bf 69 46 48 78 00 02
			09 78 08 43 04 b2 06 2d 02 d1 02 48 20 18 04 b2
			20 46 f8 bd 55 f5 ff ff fe b5 1e a0 00 68 02 90
			00 20 00 90 1f e0 02 aa 02 21 3e 20 fe f7 d5 fe
			06 46 00 2e 0f d1 00 f0 b7 f8 01 aa 04 21 40 20
			fe f7 be fe 07 46 00 2f 00 d1 0f e0 00 f0 92 f8
			00 20 01 90 03 e0 00 f0 8d f8 00 20 01 90 00 98
			40 1c c0 b2 00 90 00 98 03 28 dc db 00 bf 68 46
			40 79 04 02 68 46 00 79 04 43 68 46 c0 79 05 02
			69 46 89 79 0d 43 ac 42 01 da 28 46 fe bd 20 46
			fc e7 00 00 71 00 00 00 10 b5 01 20 ff f7 8c ff
			6c 28 09 db 02 20 ff f7 87 ff 6c 28 04 db 03 20
			ff f7 82 ff 6c 28 05 da 08 48 00 78 40 1c 07 49
			08 70 02 e0 00 20 05 49 08 70 04 48 00 78 09 28
			01 dd 01 20 10 bd 00 20 fc e7 00 00 89 00 00 20
			10 b5 04 46 00 2c 02 d0 00 20 01 f0 8b f9 05 4a
			03 21 04 20 00 f0 fe fd 00 2c 02 d0 01 20 01 f0
			81 f9 10 bd 25 02 00 00 10 b5 04 46 00 2c 02 d0
			00 20 01 f0 77 f9 05 4a 03 21 0a 20 00 f0 ea fd
			00 2c 02 d0 01 20 01 f0 6d f9 10 bd 25 02 00 00
			08 b5 08 e0 06 49 00 91 00 e0 00 bf 00 99 4a 1e
			00 92 00 29 f9 d1 01 46 40 1e 00 29 f2 d1 08 bd
			c9 29 00 00 08 b5 06 20 00 90 00 e0 00 bf 00 98
			41 1e 00 91 00 28 f9 d1 08 bd 10 b5 02 20 ff f7
			df ff 10 bd 08 b5 05 48 00 90 00 e0 00 bf 00 98
			41 1e 00 91 00 28 f9 d1 08 bd 00 00 62 0d 00 00
			08 b5 2c 20 00 90 00 e0 00 bf 00 98 41 1e 00 91
			00 28 f9 d1 08 bd 00 00 08 b5 05 48 00 90 00 e0
			00 bf 00 98 41 1e 00 91 00 28 f9 d1 08 bd 00 00
			37 02 00 00 10 b5 02 46 14 46 03 e0 ff f7 ec ff
			60 1e c4 b2 00 2c f9 dc 10 bd 70 47 8a b0 00 20
			09 90 00 26 00 27 08 90 07 90 06 90 05 90 04 90
			03 90 02 90 e1 20 40 01 fb 49 08 80 fb 48 fc 49
			08 80 fc 48 fc 49 08 60 fc 49 08 60 0a 20 fc 49
			08 70 f0 e2 01 f0 04 fe fa 48 00 68 00 28 39 d1
			58 20 01 f0 f9 fb 05 46 f7 48 00 78 00 28 2c d1
			1f 2d 05 d1 00 f0 4a fb 01 20 f3 49 08 70 17 e0
			00 2d 02 d1 01 f0 9e fb 12 e0 0c 2d 02 db 3f 20
			01 90 0d e0 02 2d 07 db 0b 2d 05 dc 68 1c 81 00
			40 18 c0 b2 01 90 03 e0 01 2d 01 d1 0f 20 01 90
			e6 48 00 78 00 28 08 d1 e5 48 02 78 e5 48 00 78
			01 99 01 f0 13 fb e1 49 08 70 7d 20 00 01 dd 49
			08 60 ad e2 d8 48 00 68 00 28 70 d1 0c 20 ff f7
			97 fe 07 46 dc 48 87 42 05 dd ff f7 63 ff 0c 20
			ff f7 8e fe 07 46 3c 46 00 bf d3 48 00 78 00 28
			73 d1 d6 48 84 42 0a da 08 98 40 1c c0 b2 08 90
			08 98 02 28 05 dd 54 20 01 f0 1c fb 01 e0 00 20
			08 90 cd 48 87 42 02 dd 59 20 01 f0 13 fb cc 48
			84 42 0a dd 04 98 40 1c c0 b2 04 90 04 98 02 28
			05 dd 59 20 01 f0 06 fb 01 e0 00 20 04 90 c5 48
			00 78 01 28 53 d1 c4 48 00 68 c4 49 88 42 02 dd
			05 20 07 90 25 e0 c0 48 00 68 c0 49 49 1f 88 42
			02 dd 04 20 07 90 1c e0 bb 48 00 68 bb 49 14 39
			88 42 02 dd 03 20 07 90 13 e0 b7 48 00 68 b7 49
			1e 39 88 42 02 dd 02 20 07 90 0a e0 b2 48 00 68
			b2 49 28 39 88 42 02 dd 01 20 07 90 01 e0 00 20
			07 90 af 48 84 42 03 dd 00 20 06 90 7a e0 bf e0
			ab 48 64 38 84 42 02 dd 01 20 06 90 72 e0 97 48
			c8 30 84 42 02 dd 02 20 06 90 6b e0 93 48 64 30
			84 42 03 dd 03 20 06 90 64 e0 a0 e0 8f 48 84 42
			02 dd 04 20 06 90 5d e0 05 20 06 90 5a e0 99 48
			00 78 02 28 52 d1 98 48 00 68 98 49 88 42 02 dd
			05 20 07 90 25 e0 94 48 00 68 94 49 49 1f 88 42
			02 dd 04 20 07 90 1c e0 8f 48 00 68 8f 49 14 39
			88 42 02 dd 03 20 07 90 13 e0 8b 48 00 68 8b 49
			1e 39 88 42 02 dd 02 20 07 90 0a e0 86 48 00 68
			86 49 28 39 88 42 02 dd 01 20 07 90 01 e0 00 20
			07 90 83 48 64 30 84 42 02 dd 00 20 06 90 21 e0
			7f 48 84 42 02 dd 01 20 06 90 1b e0 7c 48 64 38
			84 42 02 dd 02 20 06 90 14 e0 68 48 c8 30 84 42
			02 dd 03 20 06 90 0d e0 64 48 64 30 84 42 02 dd
			04 20 06 90 06 e0 05 20 06 90 03 e0 00 20 07 90
			05 20 06 90 06 99 07 98 40 18 05 28 0a dd 03 98
			40 1c c0 b2 03 90 03 98 05 28 05 dd 5a 20 01 f0
			41 fa 01 e0 00 20 03 90 66 48 00 88 84 42 11 dd
			64 48 00 88 64 49 88 42 0c dd 64 48 00 78 00 28
			05 d0 62 48 00 78 40 1e 60 49 08 70 02 e0 55 20
			01 f0 28 fa 58 48 00 68 58 49 24 39 88 42 0f dd
			5b 48 84 42 0c dd 4a 48 00 78 40 1e 48 49 08 70
			08 46 00 78 00 28 06 d1 55 20 01 f0 13 fa 02 e0
			0a 20 43 49 08 70 7d 20 c0 00 3f 49 08 60 77 e1
			50 48 00 68 00 28 6d d1 ff f7 86 fd 06 46 4e 48
			86 42 03 dc 7d 20 00 01 86 42 0e da ff f7 2a fe
			ff f7 7a fd 06 46 48 48 86 42 03 dc 7d 20 00 01
			86 42 02 da 59 20 01 f0 ed f9 3b 48 06 60 32 48
			00 78 00 28 4f d1 2a 48 00 88 00 28 07 d1 31 48
			00 78 3f 28 1a dd 3f 20 2e 49 08 70 16 e0 24 48
			00 88 0a 28 07 da 2b 48 00 78 3f 28 0e dd 3f 20
			28 49 08 70 0a e0 1e 48 00 88 fa 28 06 da 25 48
			00 78 32 28 02 dd 32 20 22 49 08 70 2f 48 00 78
			00 28 19 d1 24 48 00 68 24 49 28 39 88 42 07 dd
			1c 48 00 78 3f 28 0f dd 3f 20 1a 49 08 70 0b e0
			1d 48 00 68 26 49 88 42 06 dd 16 48 00 78 3f 28
			02 dd 3f 20 13 49 08 70 17 48 00 68 20 49 64 31
			88 42 3f dd 0f 48 00 78 3f 28 55 dd 3f 20 0d 49
			08 70 51 e0 8b e0 82 e0 66 00 00 20 26 02 00 00
			68 00 00 20 20 4e 00 00 70 00 00 20 7c 00 00 20
			91 00 00 20 74 00 00 20 61 00 00 20 84 00 00 20
			5d 00 00 20 86 00 00 20 10 27 00 00 30 f8 ff ff
			4c 1d 00 00 36 00 00 20 38 00 00 20 8a 11 00 00
			b6 03 00 00 8e 00 00 20 fc 08 00 00 90 00 00 20
			e4 0c 00 00 6c 00 00 20 88 13 00 00 87 00 00 20
			68 10 00 00 68 48 00 68 21 21 c9 01 88 42 07 dd
			66 48 00 78 3f 28 0f dd 3f 20 64 49 08 70 0b e0
			61 48 00 68 62 49 88 42 06 dd 60 48 00 78 3f 28
			02 dd 3f 20 5d 49 08 70 5e 48 00 78 00 28 09 d1
			5d 48 02 78 5d 48 01 78 58 48 00 78 01 f0 06 f9
			58 49 08 70 5a 48 00 78 02 28 08 d1 52 48 00 68
			53 49 d2 31 88 42 02 dd 5a 20 01 f0 2b f9 4e 48
			00 68 54 49 88 42 02 dd 5a 20 01 f0 23 f9 4a 48
			00 68 50 49 0a 39 88 42 0a dd 09 98 40 1c c0 b2
			09 90 09 98 05 28 05 dd 5a 20 01 f0 13 f9 01 e0
			00 20 09 90 ff 20 f5 30 47 49 08 60 78 e0 47 48
			00 68 00 28 1f d1 06 20 ff f7 62 fc 04 46 44 48
			00 78 00 28 12 d1 00 2c 03 dd ff 20 f5 30 84 42
			0a dd 05 98 40 1c c0 b2 05 90 05 98 02 28 05 dd
			5c 20 01 f0 ef f8 01 e0 00 20 05 90 ff 20 f5 30
			36 49 08 60 54 e0 37 48 00 68 00 28 1e d1 34 48
			00 78 00 28 0e d1 ff f7 9f fc 00 28 05 d0 00 20
			00 f0 b4 f8 01 20 2e 49 08 70 19 20 40 01 2d 49
			08 60 3d e0 02 98 00 28 04 d1 5d 20 01 f0 4c f9
			01 20 02 90 28 48 27 49 08 60 31 e0 27 48 00 78
			00 28 2d d1 26 48 00 88 00 28 06 d1 20 48 00 78
			00 28 02 d1 5a 20 01 f0 b5 f8 22 48 00 78 00 28
			02 d0 59 20 01 f0 ae f8 1f 48 00 78 00 28 02 d0
			54 20 01 f0 a7 f8 1d 48 00 78 00 28 02 d0 54 20
			01 f0 a0 f8 1a 48 00 78 00 28 03 d1 19 48 00 78
			01 28 02 dd 54 20 01 f0 95 f8 14 20 0f 49 08 70
			2f 20 ff f7 e7 fc 0d e5 38 00 00 20 86 00 00 20
			7c 10 00 00 84 00 00 20 5d 00 00 20 5c 00 00 20
			92 00 00 20 94 11 00 00 6c 00 00 20 7c 00 00 20
			61 00 00 20 80 00 00 20 10 27 00 00 78 00 00 20
			66 00 00 20 43 00 00 20 3f 00 00 20 3e 00 00 20
			3c 00 00 20 8d 00 00 20 30 e0 01 f0 e9 fa 18 48
			00 68 00 28 0a d1 58 20 01 f0 de f8 00 28 01 d1
			01 f0 90 f8 13 48 12 49 08 60 1f e0 12 48 00 78
			00 28 1b d1 11 48 00 78 00 28 02 d0 54 20 01 f0
			49 f8 0f 48 00 78 00 28 02 d0 54 20 01 f0 42 f8
			0c 48 00 78 00 28 03 d1 0b 48 00 78 01 28 02 dd
			54 20 01 f0 37 f8 14 20 03 49 08 70 cd e7 00 00
			74 00 00 20 70 17 00 00 78 00 00 20 3f 00 00 20
			3e 00 00 20 3c 00 00 20 8d 00 00 20 00 28 08 d0
			08 49 c9 69 01 22 12 04 91 43 89 18 05 4a d1 61
			06 e0 04 49 c9 69 01 22 12 04 91 43 01 4a d1 61
			70 47 00 00 00 00 02 40 03 48 c0 69 01 21 09 04
			88 43 01 49 c8 61 70 47 00 00 02 40 01 46 00 29
			08 d0 01 29 15 d1 0c 48 00 68 42 07 52 0f 0b 48
			d0 40 70 47 08 48 00 68 80 06 40 0f 00 28 01 d1
			07 48 f6 e7 04 48 00 68 80 06 42 0f 03 48 d0 40
			ef e7 02 48 ed e7 00 00 00 00 02 40 00 24 f4 00
			00 12 7a 00 10 b5 05 20 00 f0 98 f8 00 28 01 d0
			01 20 10 bd 00 20 fc e7 10 b5 09 20 00 f0 8e f8
			00 28 01 d0 01 20 10 bd 00 20 fc e7 03 48 c0 69
			c0 03 c0 0f 01 21 48 40 70 47 00 00 00 00 02 40
			70 47 10 b5 01 20 80 07 00 f0 90 fa c4 b2 64 06
			64 0e 20 46 10 bd 00 00 04 49 89 69 89 08 89 00
			82 07 92 0f 11 43 01 4a 91 61 70 47 00 00 01 40
			05 49 89 69 0c 22 91 43 82 00 0c 23 1a 40 11 43
			01 4a 91 61 70 47 00 00 00 00 01 40 70 b5 0b 48
			85 6b 00 24 0e e0 01 20 a0 40 28 40 00 28 08 d0
			a0 00 07 49 08 58 00 28 03 d0 a1 00 04 4a 50 58
			80 47 64 1c 10 2c ee d3 70 bd 00 00 00 00 01 40
			b0 00 00 20 10 28 04 da 01 21 81 40 03 4a 91 63
			03 e0 00 21 c9 43 01 4a 91 63 70 47 00 00 01 40
			10 b5 02 46 10 2a 01 da 10 48 00 e0 10 bd 00 bf
			72 b6 00 bf 00 29 0a d1 03 69 01 24 94 40 a3 43
			03 61 83 68 01 24 94 40 23 43 83 60 09 e0 83 68
			01 24 94 40 23 43 83 60 03 69 01 24 94 40 23 43
			03 61 00 bf 62 b6 00 bf 00 bf df e7 00 00 01 40
			01 48 80 6b 70 47 00 00 00 00 01 40 10 b5 01 46
			10 29 01 da 0a 4a 01 e0 00 20 10 bd 00 bf 72 b6
			00 bf 10 68 01 24 8c 40 20 40 00 28 01 d0 01 20
			00 e0 00 20 03 46 00 bf 62 b6 00 bf 18 46 ec e7
			00 00 01 40 ff b5 81 b0 04 46 15 46 1e 46 11 48
			04 70 01 20 0f 49 48 70 89 1c 02 a8 fe f7 06 f9
			0c 48 85 71 c1 1d 30 46 fe f7 00 f9 09 48 c0 1d
			fe f7 f2 f8 00 90 07 48 81 79 00 98 fe f7 e1 f8
			04 48 00 f0 4f f8 07 46 00 f0 9d f8 38 46 05 b0
			f0 bd 00 00 15 01 00 20 10 b5 00 bf 1f 48 00 68
			40 08 40 00 1d 49 08 60 08 46 00 68 04 21 88 43
			1a 49 08 60 00 bf 00 20 19 49 89 69 03 22 92 05
			91 43 82 05 03 23 9b 05 1a 40 11 43 14 4a 91 61
			00 bf 00 bf 11 46 89 69 9a 00 91 43 02 06 9b 00
			1a 40 11 43 0e 4a 91 61 00 bf 02 21 0c 20 00 f0
			3b f9 02 21 0b 20 00 f0 37 f9 00 21 0c 20 00 f0
			69 f9 00 21 0b 20 00 f0 65 f9 00 21 0c 20 ff f7
			4f ff 00 21 0b 20 ff f7 4b ff 10 bd 00 c0 00 40
			00 00 01 40 70 b5 04 46 fe f7 ac fc 21 78 49 06
			08 0e fe f7 03 fc 01 28 03 d1 fe f7 bb fc 01 20
			70 bd 00 25 0d e0 a0 1c fe f7 86 f8 46 5d 30 46
			fe f7 f4 fb 01 28 03 d1 fe f7 ac fc 01 20 ef e7
			6d 1c 60 78 a8 42 ee d8 fe f7 5e fc 21 78 49 00
			49 1c c8 b2 fe f7 e2 fb 01 28 03 d1 fe f7 9a fc
			01 20 dd e7 00 25 17 e0 e0 1d fe f7 65 f8 06 46
			a0 79 40 1e a8 42 01 d1 01 20 00 e0 00 20 01 46
			30 46 fe f7 4b fb e0 1d fe f7 56 f8 46 1c e1 1d
			30 46 fe f7 5b f8 6d 1c a0 79 a8 42 e4 d8 fe f7
			79 fc 00 20 bc e7 70 47 70 b5 05 46 fe f7 5a fc
			29 78 49 06 08 0e fe f7 b1 fb 01 28 03 d1 fe f7
			69 fc 01 20 70 bd 00 24 0d e0 a8 1c fe f7 34 f8
			06 5d 30 46 fe f7 a2 fb 01 28 03 d1 fe f7 5a fc
			01 20 ef e7 64 1c 68 78 a0 42 ee d8 00 24 0d e0
			e8 1d fe f7 21 f8 06 5d 30 46 fe f7 8f fb 01 28
			03 d1 fe f7 47 fc 01 20 dc e7 64 1c a8 79 a0 42
			ee d8 fe f7 3f fc 00 20 d4 e7 00 00 37 b5 04 46
			0b 48 04 70 01 20 0a 49 48 70 89 1c 01 a8 fe f7
			0d f8 02 20 06 49 88 71 c9 1d 02 a8 fe f7 06 f8
			03 48 ff f7 b1 ff 05 46 ff f7 ad ff 28 46 3e bd
			15 01 00 20 f8 b5 05 46 0e 46 17 46 10 2d 01 da
			36 4c 00 e0 f8 bd 00 21 28 46 ff f7 91 fe 00 2e
			06 d0 01 2e 0f d0 02 2e 18 d0 03 2e 2c d1 20 e0
			a0 6a 01 21 a9 40 88 43 a0 62 20 6b 01 21 a9 40
			88 43 20 63 21 e0 a0 6a 01 21 a9 40 08 43 a0 62
			20 6b 01 21 a9 40 88 43 20 63 16 e0 a0 6a 01 21
			a9 40 88 43 a0 62 20 6b 01 21 a9 40 08 43 20 63
			0b e0 a0 6a 01 21 a9 40 08 43 a0 62 20 6b 01 21
			a9 40 08 43 20 63 00 e0 c4 e7 00 bf a8 00 18 49
			0f 50 e1 6b 01 20 a8 40 81 43 e1 63 20 6a 01 21
			a9 40 08 43 20 62 11 20 00 28 0c db 11 49 09 68
			c3 06 db 0e 01 22 9a 40 11 40 00 29 01 d0 01 21
			02 e0 00 21 00 e0 00 21 00 29 0d d1 11 20 00 28
			05 db c2 06 d2 0e 01 21 91 40 06 4a 11 60 00 bf
			00 21 11 20 fe f7 42 f9 00 bf 93 e7 00 00 01 40
			b0 00 00 20 00 e1 00 e0 10 b5 02 46 10 2a 01 da
			17 48 00 e0 10 bd 00 29 04 d0 01 29 0d d0 02 29
			21 d1 15 e0 43 6c 01 24 94 40 23 43 43 64 83 6c
			01 24 94 40 a3 43 83 64 16 e0 43 6c 01 24 94 40
			a3 43 43 64 83 6c 01 24 94 40 23 43 83 64 0b e0
			43 6c 01 24 94 40 a3 43 43 64 83 6c 01 24 94 40
			a3 43 83 64 00 e0 00 bf 00 bf 00 bf d2 e7 00 00
			00 00 01 40 10 b5 02 46 10 2a 01 da 0b 48 00 e0
			10 bd 00 bf 72 b6 00 bf 01 29 05 d1 43 68 01 24
			94 40 23 43 43 60 04 e0 44 68 01 23 93 40 9c 43
			44 60 00 bf 62 b6 00 bf 00 bf e9 e7 00 00 01 40
			10 b5 01 20 81 07 c8 60 01 48 00 68 80 47 10 bd
			04 00 00 20 10 b5 01 20 02 49 c8 60 02 48 00 68
			80 47 10 bd 00 10 00 40 08 00 00 20 01 46 48 68
			70 47 01 46 08 68 c0 07 c0 0f 70 47 f8 b5 04 46
			0e 46 15 46 01 20 ff f7 19 fd 7d 21 c9 00 00 90
			fd f7 be fe 70 43 07 46 a7 60 67 60 00 20 c0 43
			e0 60 20 68 08 21 88 43 08 30 20 60 c8 06 84 42
			09 d1 0a 48 05 60 02 21 08 20 fe f7 e3 f8 08 20
			fe f7 98 f8 08 e0 06 48 05 60 02 21 09 20 fe f7
			d9 f8 09 20 fe f7 8e f8 f8 bd 00 00 04 00 00 20
			08 00 00 20 01 68 49 08 49 00 49 1c 01 60 70 47
			10 b5 ff f7 e9 fd 10 bd 0d 48 41 68 0d 4b c9 01
			0e d5 41 68 c9 03 0b d4 00 21 c9 43 41 60 41 6f
			82 15 91 43 41 67 08 4a 00 21 51 70 d1 60 19 70
			19 78 04 4a 89 00 08 32 52 58 02 49 10 47 00 00
			00 c0 00 40 0c 00 00 20 f0 00 00 20 01 21 0d 4a
			0b 48 89 04 11 60 bf f3 4f 8f bf f3 6f 8f 51 17
			41 60 41 6f 82 15 91 43 41 67 00 21 81 60 01 68
			49 08 49 00 01 60 01 68 04 22 91 43 01 60 70 47
			00 c0 00 40 80 e1 00 e0 0c 48 0d 49 89 6b 00 29
			08 d0 0b 49 89 6b 3f 22 12 02 11 40 09 0a 09 4a
			11 61 0a e0 08 49 41 60 08 49 01 60 81 68 3f 22
			12 02 11 40 09 0a 03 4a 11 61 70 47 00 30 00 40
			00 00 02 40 00 e0 00 40 02 00 00 80 01 4f 4c 46
			e2 48 c0 69 01 21 09 04 88 43 e0 49 c8 61 08 46
			c0 69 10 21 88 43 dd 49 c8 61 ff f7 cd ff 00 f0
			03 fa fe f7 c9 fa 00 f0 fb fd 00 f0 fe f9 ff f7
			7f ff 00 20 ff f7 60 f8 01 20 00 f0 db f9 53 20
			00 f0 6a fd 05 46 2d 07 2d 0f 00 2d 01 d1 0a 24
			11 e0 01 2d 01 d1 3c 24 0d e0 02 2d 01 d1 82 24
			09 e0 03 2d 01 d1 aa 24 05 e0 04 2d 02 d1 ff 24
			05 34 00 e0 0a 24 32 2c 0b db 78 2c 09 da c4 48
			c4 49 08 60 04 20 c4 49 08 70 02 20 c3 49 08 70
			34 e0 78 2c 0b db a0 2c 09 da c1 48 bd 49 08 60
			06 20 bd 49 08 70 01 20 be 49 08 70 26 e0 a0 2c
			0b db fa 2c 09 da bc 48 b6 49 08 60 06 20 b6 49
			08 70 01 20 b7 49 08 70 18 e0 fa 2c 0d db ff 20
			af 30 84 42 09 da b5 48 ae 49 08 60 06 20 ae 49
			08 70 02 20 af 49 08 70 08 e0 b1 48 a9 49 08 60
			04 20 a9 49 08 70 02 20 a8 49 08 70 a6 49 08 78
			c1 0f 09 18 49 10 ab 4a 11 70 10 46 00 78 08 21
			08 40 c0 10 a8 49 08 70 10 46 00 78 04 21 08 40
			80 10 a6 49 08 70 10 46 00 78 02 21 08 40 40 10
			a3 49 08 70 10 46 00 78 c0 07 c0 0f a1 49 08 70
			00 f0 34 fc 00 f0 4a fc 00 f0 6c fb 00 f0 42 fb
			00 20 fe f7 bd ff 00 bf ff f7 37 f8 00 f0 4e fc
			00 28 f9 d0 00 f0 4f fe 15 e0 00 f0 51 fe 96 48
			00 78 00 28 01 d0 00 f0 fd fb 94 48 00 78 01 28
			04 d1 93 48 00 78 01 28 00 d1 05 e0 91 48 00 78
			00 28 00 d1 00 e0 e8 e7 00 bf 01 20 8e 49 08 70
			fe f7 0b ff 52 20 00 f0 2f fc 05 46 01 20 8b 49
			08 70 00 2d 01 d1 00 f0 dd fb 00 f0 29 fe 5e 20
			00 f0 22 fc 05 46 02 2d 01 d0 00 f0 d3 fb 00 f0
			1f fe fe f7 c2 ff 00 f0 1b fe 81 48 00 78 00 f0
			13 fc 05 46 02 2d 01 d0 00 f0 c4 fb 00 f0 10 fe
			00 f0 0e fe 7a 48 00 78 00 28 03 d0 fe f7 04 ff
			78 49 08 60 fe f7 a9 ff 75 48 00 78 00 28 03 d0
			2c 20 fe f7 d5 fe c6 b2 55 2e 25 dd fa 2c 05 db
			14 20 71 49 08 70 71 49 08 70 8a e0 a0 2c 05 db
			0f 20 6d 49 08 70 6d 49 08 70 82 e0 78 2c 05 db
			0a 20 69 49 08 70 69 49 08 70 7a e0 32 2c 05 db
			0a 20 65 49 08 70 65 49 08 70 72 e0 0a 20 62 49
			08 70 62 49 08 70 6c e0 4b 2e 25 dd fa 2c 05 db
			1e 20 5d 49 08 70 5d 49 08 70 62 e0 a0 2c 05 db
			19 20 59 49 08 70 59 49 08 70 5a e0 78 2c 05 db
			14 20 55 49 08 70 55 49 08 70 52 e0 32 2c 05 db
			0a 20 51 49 08 70 51 49 08 70 4a e0 0a 20 4e 49
			08 70 4e 49 08 70 44 e0 32 2e 25 dd fa 2c 05 db
			28 20 49 49 08 70 49 49 08 70 3a e0 a0 2c 05 db
			28 20 45 49 08 70 45 49 08 70 32 e0 78 2c 05 db
			1c 20 41 49 08 70 41 49 08 70 2a e0 32 2c 05 db
			0f 20 3d 49 08 70 3d 49 08 70 22 e0 0a 20 3a 49
			08 70 3a 49 08 70 1c e0 a0 2c 05 db 3f 20 36 49
			08 70 36 49 08 70 14 e0 78 2c 05 db 32 20 32 49
			08 70 32 49 08 70 0c e0 32 2c 05 db 19 20 2e 49
			08 70 2e 49 08 70 04 e0 14 20 2b 49 08 70 2b 49
			08 70 fe f7 0a ff ff f7 1b fb 58 20 00 f0 5c fb
			01 20 27 49 08 70 1f 48 00 78 00 28 01 d1 ff f7
			6b fa 0c e0 00 f0 54 fd 17 48 00 78 00 28 03 d1
			1a 48 00 78 01 28 02 dd 54 20 00 f0 c3 fa ff f7
			f5 fa 01 28 ee d0 fe f7 21 ff 00 00 00 00 02 40
			38 33 00 00 2c 00 00 20 30 00 00 20 92 00 00 20
			54 33 00 00 36 00 00 20 7e 33 00 00 a8 33 00 00
			1c 33 00 00 31 00 00 20 32 00 00 20 33 00 00 20
			34 00 00 20 35 00 00 20 3c 00 00 20 5a 00 00 20
			55 00 00 20 8b 00 00 20 5b 00 00 20 8d 00 00 20
			51 00 00 20 38 00 00 20 85 00 00 20 86 00 00 20
			42 00 00 20 00 28 09 d0 0a 49 09 78 00 29 05 d1
			00 bf 62 b6 00 bf 07 49 08 70 0a e0 00 28 08 d1
			04 49 09 78 00 29 04 d0 00 bf 72 b6 00 bf 01 49
			08 70 70 47 a8 00 00 20 70 47 10 b5 ff f7 5c fa
			00 f0 16 fa 00 f0 ec f9 00 f0 f4 f9 00 f0 ca f9
			fe f7 bc fd 10 bd 00 00 70 b5 06 46 1c 4d 1d 4c
			01 20 ff f7 a1 fa 06 2e 0b d1 e0 69 01 21 49 04
			88 43 40 18 e0 61 e0 69 89 00 88 43 40 18 e0 61
			16 e0 69 68 09 01 89 0e 10 22 11 43 89 05 3f 22
			92 05 11 40 08 46 69 68 91 43 01 43 69 60 e0 69
			01 21 49 04 88 43 e0 61 e0 69 89 00 88 43 e0 61
			69 68 89 05 89 0e 10 22 11 43 09 01 3f 22 12 01
			11 40 08 46 69 68 91 43 01 43 69 60 70 bd 00 00
			00 70 00 40 00 00 02 40 70 b5 06 46 17 4c 18 4d
			01 20 ff f7 6d fa 07 2e 06 d1 e8 69 01 21 89 04
			88 43 40 18 e8 61 12 e0 61 68 09 01 89 0e 20 22
			11 43 89 05 3f 22 92 05 11 40 08 46 61 68 91 43
			01 43 61 60 e8 69 01 21 89 04 88 43 e8 61 61 68
			89 05 89 0e 20 22 11 43 09 01 3f 22 12 01 11 40
			08 46 61 68 91 43 01 43 61 60 70 bd 00 70 00 40
			00 00 02 40 70 b5 02 46 31 49 32 48 13 00 fd f7
			6b fd 08 05 06 07 08 09 0a 1a 34 4a 00 bf 00 bf
			00 bf 00 bf 00 bf 4c 68 a4 05 a4 0e 01 25 95 40
			ac 43 24 01 3f 25 2d 01 2c 40 23 46 4c 68 ac 43
			1c 43 4c 60 42 e0 4c 68 a4 05 a4 0e 95 1e 01 26
			ae 40 b4 43 24 01 3f 25 2d 01 2c 40 23 46 4c 68
			ac 43 1c 43 4c 60 c3 69 01 24 64 04 a3 43 c3 61
			c3 69 a4 00 a3 43 c3 61 28 e0 4c 68 a4 05 a4 0e
			95 1e 01 26 ae 40 b4 43 24 01 3f 25 2d 01 2c 40
			23 46 4c 68 ac 43 1c 43 4c 60 c3 69 01 24 a4 04
			a3 43 c3 61 12 e0 4b 68 3f 24 24 01 a3 43 4b 60
			c3 69 01 24 64 04 a3 43 c3 61 c3 69 a4 00 a3 43
			c3 61 c3 69 64 10 a3 43 c3 61 00 bf 00 bf 70 bd
			00 70 00 40 00 00 02 40 70 b5 05 46 3c 4c 2b 00
			fd f7 02 fd 09 1a 2a 49 4a 69 6e 6a 6f 06 73 00
			60 68 3f 21 89 05 88 43 1f 21 c9 05 40 18 60 60
			60 68 3f 21 09 01 08 43 60 60 01 20 ff f7 ac f9
			01 20 ff f7 b5 f9 59 e0 61 68 89 05 89 0e 01 22
			aa 40 11 43 09 01 3f 22 12 01 11 40 08 46 61 68
			91 43 01 43 61 60 49 e0 61 68 09 01 89 0e 01 22
			aa 40 11 43 89 05 3f 22 92 05 11 40 08 46 61 68
			91 43 01 43 61 60 61 68 89 05 89 0e 01 22 aa 40
			11 43 09 01 3f 22 12 01 11 40 08 46 61 68 91 43
			01 43 61 60 2a e0 00 bf 61 68 09 01 89 0e 01 22
			aa 40 11 43 89 05 3f 22 92 05 11 40 08 46 61 68
			91 43 01 43 61 60 61 68 89 05 89 0e 01 22 aa 40
			11 43 09 01 3f 22 12 01 11 40 08 46 61 68 91 43
			01 43 61 60 0a e0 00 bf 28 46 ff f7 ad fe 05 e0
			00 bf 28 46 ff f7 e8 fe 00 e0 00 bf 00 bf 70 bd
			00 70 00 40 07 48 08 49 09 78 01 29 00 d1 70 47
			01 21 05 4a 11 70 05 49 41 60 00 21 c9 43 c1 60
			00 bf f4 e7 00 70 00 40 00 00 00 20 01 0c 00 00
			06 49 ca 68 ca 60 40 23 13 40 00 2b 04 d0 00 20
			00 e0 40 1c 05 28 fc d9 70 47 00 00 00 70 00 40
			70 b5 04 46 1e 4d 08 2c 01 db 00 20 70 bd 20 46
			ff f7 52 ff 00 bf 1a 48 00 68 40 08 40 00 40 1c
			17 49 08 60 00 bf 64 23 00 22 04 21 28 46 00 f0
			29 fb 00 28 22 d0 20 46 ff f7 d4 fe 06 2c 09 d1
			a0 1e 81 00 28 46 10 30 40 58 86 05 b6 0d 0a 20
			46 43 11 e0 07 2c 09 d1 a0 1e 81 00 28 46 10 30
			40 58 86 05 b6 0d 06 20 46 43 05 e0 a1 00 28 46
			10 30 40 58 86 05 b6 0d 30 46 c7 e7 00 20 c5 e7
			00 70 00 40 10 b5 00 21 04 20 ff f7 21 f9 10 bd
			10 b5 00 21 04 20 ff f7 2d fb 01 21 04 20 ff f7
			17 f9 10 bd 10 b5 04 46 00 2c 04 d0 01 21 04 20
			ff f7 20 fb 03 e0 00 21 04 20 ff f7 1b fb 10 bd
			10 b5 00 21 0a 20 ff f7 df fa 00 21 0a 20 ff f7
			ff f8 10 bd 10 b5 00 21 05 20 ff f7 f9 f8 10 bd
			10 b5 00 21 05 20 ff f7 05 fb 01 21 05 20 ff f7
			ef f8 10 bd 10 b5 04 46 00 2c 04 d0 01 21 05 20
			ff f7 f8 fa 03 e0 00 21 05 20 ff f7 f3 fa 10 bd
			10 b5 00 21 09 20 ff f7 db f8 10 bd 10 b5 00 21
			09 20 ff f7 e7 fa 01 21 09 20 ff f7 d1 f8 10 bd
			10 b5 04 46 00 2c 04 d0 01 21 09 20 ff f7 da fa
			03 e0 00 21 09 20 ff f7 d5 fa 10 bd 30 b5 03 46
			10 48 04 78 10 48 00 78 98 42 01 dd 0e 48 03 70
			0e 48 01 70 0e 48 02 70 91 42 00 da 0a 46 0a 48
			00 78 90 42 02 dd 07 48 02 70 03 e0 06 48 00 78
			04 4d 28 70 03 48 00 78 84 42 01 d0 05 20 30 bd
			00 20 fc e7 85 00 00 20 86 00 00 20 5c 00 00 20
			5d 00 00 20 02 48 01 69 02 69 0a 43 02 61 70 47
			00 a0 00 40 10 b5 04 46 00 f0 82 fa 00 20 fe f7
			d5 ff ff f7 87 ff 20 46 00 f0 76 f8 00 f0 2a f8
			10 bd 00 00 70 b5 04 46 00 20 fe f7 e7 ff 60 43
			05 46 00 bf 0b 48 0c 49 08 60 00 bf 0b 48 05 60
			45 60 03 20 09 49 88 60 09 48 00 68 40 21 88 43
			40 30 07 49 08 60 00 bf 00 20 03 49 08 60 00 bf
			70 bd 00 00 51 e5 cc 1a 00 8c 00 40 00 80 00 40
			00 00 02 40 00 bf 00 bf 00 bf 00 bf 00 bf bf f3
			4f 8f 00 bf 00 bf 00 bf 06 48 07 49 c8 60 00 bf
			00 bf 00 bf bf f3 4f 8f 00 bf 00 bf 00 bf 00 bf
			00 bf fd e7 04 00 fa 05 00 ed 00 e0 10 b5 00 24
			ff f7 16 ff 00 bf 0d e0 00 20 ff f7 1b ff 01 20
			fe f7 f8 fb 01 20 ff f7 15 ff 03 20 fe f7 f2 fb
			60 1c c4 b2 1e 2c ef db 10 bd 00 00 10 b5 03 4a
			01 21 88 07 ff f7 6a fa 10 bd 00 00 e9 03 00 00
			10 b5 01 20 80 07 ff f7 95 fa 10 bd 10 b5 01 20
			80 07 ff f7 56 fa 10 bd fe b5 05 46 00 27 00 f0
			ff f9 01 95 00 20 3e 49 08 70 ff f7 27 ff fe f7
			af fb 00 20 ff f7 2c ff fe f7 97 fb 01 20 ff f7
			27 ff 00 24 1f e0 37 48 00 78 00 28 03 d0 58 2d
			01 d1 ff f7 ef fe 00 f0 e3 f9 00 bf 30 48 00 78
			00 28 fb d0 00 f0 dc f9 06 20 01 1b 01 98 08 41
			c0 07 c0 0f 00 90 00 98 ff f7 0a ff 00 20 28 49
			08 70 60 1c c4 b2 07 2c dd db 00 f0 c9 f9 00 24
			28 e0 24 48 00 78 00 28 03 d0 58 2d 01 d1 ff f7
			c9 fe 00 f0 bd f9 00 bf 1d 48 00 78 00 28 fb d0
			00 f0 b6 f9 00 2c 03 d1 ff f7 da fe fe f7 68 fb
			00 20 17 49 08 70 fe f7 4f ff 06 46 06 2c 07 d0
			00 2c 05 d0 05 20 01 1b 30 46 88 40 38 43 c7 b2
			60 1c c4 b2 07 2c d4 db 00 f0 9a f9 00 bf 0c 48
			00 78 00 28 fb d0 00 f0 93 f9 ff f7 bf fe fe f7
			47 fb 00 20 ff f7 c4 fe 00 20 05 49 08 70 fe f7
			2c fb fe f7 2a fb 00 f0 83 f9 38 46 fe bd 00 00
			3d 00 00 20 3c 00 00 20 fe b5 05 46 00 27 00 f0
			77 f9 01 95 00 20 3c 49 08 70 ff f7 9f fe fe f7
			27 fb 00 20 ff f7 a4 fe fe f7 0f fb 01 20 ff f7
			9f fe 00 24 1f e0 35 48 00 78 00 28 03 d0 58 2d
			01 d1 ff f7 67 fe 00 f0 5b f9 00 bf 2e 48 00 78
			00 28 fb d0 00 f0 54 f9 06 20 01 1b 01 98 08 41
			c0 07 c0 0f 00 90 00 98 ff f7 82 fe 00 20 26 49
			08 70 60 1c c4 b2 07 2c dd db 00 f0 41 f9 00 24
			24 e0 22 48 00 78 00 28 03 d0 58 2d 01 d1 ff f7
			41 fe 00 f0 35 f9 00 bf 1b 48 00 78 00 28 fb d0
			00 f0 2e f9 00 2c 03 d1 ff f7 52 fe fe f7 e0 fa
			00 20 15 49 08 70 fe f7 c7 fe 06 46 06 20 01 1b
			30 46 88 40 38 43 c7 b2 60 1c c4 b2 07 2c d8 db
			00 f0 16 f9 00 bf 0c 48 00 78 00 28 fb d0 00 f0
			0f f9 ff f7 3b fe fe f7 c3 fa 00 20 ff f7 40 fe
			00 20 05 49 08 70 fe f7 a8 fa fe f7 a6 fa 00 f0
			ff f8 38 46 fe bd 00 00 3d 00 00 20 3c 00 00 20
			00 20 2d 49 08 70 2d 49 08 70 2d 49 08 70 2d 49
			08 70 2d 49 08 70 2d 49 08 70 2d 49 08 70 2d 49
			08 70 01 20 2c 49 08 70 00 20 48 70 88 70 2b 49
			08 70 2b 49 08 70 2b 49 08 70 2b 49 08 70 03 20
			2a 49 08 70 00 20 2a 49 08 70 2a 49 08 70 2a 49
			08 70 2a 49 08 80 40 1e 29 49 08 80 00 20 29 49
			08 70 29 49 08 70 3f 20 28 49 08 70 28 49 08 70
			00 20 28 49 08 70 28 49 08 70 28 49 08 70 3f 20
			27 49 08 70 27 49 08 70 01 20 27 49 08 70 27 49
			08 70 00 20 26 49 08 70 26 49 08 70 02 20 26 49
			08 70 03 20 25 49 08 70 00 20 25 49 08 70 25 49
			08 70 25 49 08 70 70 47 3c 00 00 20 42 00 00 20
			43 00 00 20 3e 00 00 20 3f 00 00 20 40 00 00 20
			41 00 00 20 4c 00 00 20 04 01 00 20 4d 00 00 20
			4f 00 00 20 50 00 00 20 51 00 00 20 52 00 00 20
			53 00 00 20 54 00 00 20 55 00 00 20 56 00 00 20
			58 00 00 20 5a 00 00 20 5b 00 00 20 5c 00 00 20
			5d 00 00 20 5e 00 00 20 61 00 00 20 84 00 00 20
			85 00 00 20 86 00 00 20 87 00 00 20 88 00 00 20
			89 00 00 20 8a 00 00 20 8b 00 00 20 8c 00 00 20
			8d 00 00 20 92 00 00 20 36 00 00 20 f8 b5 00 bf
			00 bf 00 bf 00 bf 07 20 fe f7 16 f9 40 00 ff 30
			ff 30 02 30 7d 21 c9 00 48 43 07 46 10 49 fc f7
			75 ff 04 46 06 20 fe f7 07 f9 40 00 ff 30 ff 30
			02 30 7d 21 c9 00 48 43 07 46 09 49 fc f7 66 ff
			05 46 64 1b 64 26 c8 20 00 90 b4 42 01 da 00 20
			f8 bd 00 98 84 42 01 dd 02 20 f9 e7 01 20 f7 e7
			ff 03 00 00 78 b5 04 46 0d 46 1e 46 7d 20 c0 00
			70 43 00 90 00 bf 20 68 28 40 90 42 01 d1 01 20
			78 bd 00 98 40 1e 00 90 fe f7 a4 f9 00 98 00 28
			f1 d1 00 bf f4 e7 10 b5 01 20 ff f7 8b fd 10 bd
			00 bf 07 48 07 49 08 60 00 bf 00 bf 01 20 06 49
			c8 60 00 bf 00 bf 00 20 02 49 08 60 00 bf 70 47
			51 e5 cc 1a 00 8c 00 40 00 80 00 40 00 00 00 01
			01 01 00 01 00 00 01 01 01 00 00 00 00 01 00 01
			00 01 01 00 00 01 01 00 00 00 01 00 01 00 00 01
			00 00 01 01 01 00 00 00 00 01 00 01 00 01 01 00
			00 01 01 00 00 01 00 01 00 00 00 01 00 00 01 01
			01 00 00 00 01 01 01 00 00 01 01 00 01 00 00 01
			00 00 00 01 00 01 00 01 01 00 01 01 00 00 00 01
			00 01 00 00 00 01 00 01 00 00 01 00 00 00 01 01
			01 01 00 01 01 00 01 00 00 01 00 00 00 01 00 01
			00 01 01 00 01 01 00 00 00 01 00 01 00 00 00 01
			00 01 00 00 01 00 00 00 01 01 01 01 00 01 01 00
			01 00 00 01 00 00 00 01 00 01 01 01 01 00 01 01
			00 00 00 00 f4 33 00 00 00 00 00 20 b0 00 00 00
			1c 06 00 00 a4 34 00 00 b0 00 00 20 70 04 00 00
			2c 06 00 00 00 00 00 00 00 00 00 00 00 00 00 00
			00 00 00 00 00 00 00 00 45 07 00 00 fd 06 00 00
			3d 06 00 00 7d 06 00 00 ad 06 00 00 6d 07 00 00
			00 00 00 00 00 00 00 00 00 00 00 00 00 00 00 00
			00 00 00 00 00 00 00 00 00 00 00 00 00 00 00 00
			00 00 00 00 00 00 00 00 00 00 00 00 00 00 00 00
			00 00 00 00 00 00 00 00 00 00 00 00 00 00 00 00
			00 00 00 00 00 00 00 00 00 00 00 00 00 00 00 00
			00 00 00 00 00 00 00 00 00 00 00 00 00 00 00 00
			00 00 00 00 00 00 00 00 00 00 00 00 00 00 00 00
			00 00 00 00 00 00 00 00 00 02 00 08 01 07 04 fe
			d2 34 55 34
		];

		qcom,vooc-max-input-volt-support = <10000>;     //10V
		qcom,vooc-max-input-current-support = <6500>;   //6A
		vooc_charge_strategy_30w {
			strategy_1 {
				capacity_range = <0 75>;
				temp_range = <120 160>;
				input_current = <4000 4450 0
												3000 4470 0
												2000 4480 0>;
				};
			strategy_2 {
				capacity_range = <0 75>;
				temp_range = <160 410>;
				input_current = <6000 4200 900
												5000 4200 0
												4500 4450 0
												4000 4450 0
												3000 4470 0
												2000 4480 0>;
			};
			strategy_3 {
				capacity_range = <0 75>;
				temp_range = <410 420>;
				input_current = <4000 4470 0
												2000 4480 0>;
			};
			strategy_4 {
				capacity_range = <0 75>;
				temp_range = <420 425>;
				input_current = <4000 4480 0>;
			};
			strategy_5 {
				capacity_range = <0 75>;
				temp_range = <425 435>;
				input_current = <3000 4480 0>;
			};
		};

		vooc_charge_strategy_65w {
			strategy_1 {
				capacity_range = <0 50>;
				temp_range = <120 160>;
				input_current = <6000 4200 0
												4000 4454 0
												2000 4494 0
												1500 4500 0>;
			};
			strategy_2 {
				capacity_range = <0 50>;
				temp_range = <160 370>;
				input_current = <6500 4200 0
												6000 4250 300
												5500 4300 400
												4500 4454 780
												3500 4454 0
												2000 4494 0
												1500 4500 0>;
			};
			strategy_3 {
				capacity_range = <0 90>;
				temp_range = <370 430>;
				input_current = <6500 4200 0
												6000 4250 300
												5500 4300 400
												4500 4454 780
												3500 4454 0
												2000 4494 0
												1600 4500 0>;
			};
		};
	};
};


&i2c9 {
	status = "okay";
	clock-frequency = <400000>;

	/* AWINIC AW8697 Haptic */
	aw8697_haptic@5A {
		status = "okay";
		compatible = "awinic,aw8697_haptic";
		reg = <0x5A>;
		reset-gpio = <&pio 110 0x00>;
		irq-gpio = <&pio 135 0x00>;
		qcom,device_id = <815>;//19065

		support_promise_vib;
		pinctrl-names = "default";
		pinctrl-0 = <&aw_irq_gpio_default>;
	};
};

&pio{
	aw_irq_gpio_default: aw_irq_gpio_default {
		pins_cmd_dat {
			pinmux = <PINMUX_GPIO135__FUNC_GPIO135>;
			input-enable;
			slew-rate = <0>;
			bias-pull-up;
		};
	};
};

&i2c11 {

	status = "okay";
	clock-frequency = <100000>;

	mp2650-charger@5c {
		status = "okay";
		compatible = "oplus,mp2650-charger";
		reg = <0x5c 0>;

		qcom,mps_otg_en-gpio = <&pio 129 0x00>;		//check
		pinctrl-names = "mps_otg_en_active", "mps_otg_en_sleep", "mps_otg_en_default";
		pinctrl-0 = <&mps_otg_en_active>;
		pinctrl-1 = <&mps_otg_en_sleep>;
		pinctrl-2 = <&mps_otg_en_default>;
	};
};

&mt6360_pmu {
	core {
		sda_sizesel = <3>;
		sda_drvsrsel = <1>;
	};
	chg {
		support_hvdcp;
	};
};

&pio {
	charger_pins_default: eint0default {
	};

	charger_pins_eint_output0: charger_gpio_as_output_low {		//check
		pins_cmd_dat {
			pinmux = <PINMUX_GPIO192__FUNC_GPIO192>;
			slew-rate = <1>;
			output-low;
		};
	};

	charger_pins_eint_output1: charger_gpio_as_output_high {	//check
		pins_cmd_dat {
			pinmux = <PINMUX_GPIO192__FUNC_GPIO192>;
			slew-rate = <1>;
			output-high;
		};
	};

	ship_sleep_gpio: ship_sleep {
		pins_cmd_dat {
			pinmux = <PINMUX_GPIO27__FUNC_GPIO27>;		//check
			slew-rate = <1>;
			output-low;
		};
	};

	ship_active_gpio: ship_active {
		pins_cmd_dat {
			pinmux = <PINMUX_GPIO27__FUNC_GPIO27>;		//check
			slew-rate = <1>;
			output-high;
		};
	};

	dischg_enable: dischg_enable {
		pins_cmd_dat {
			pinmux = <PINMUX_GPIO51__FUNC_GPIO51>;		//check
			output-enable;
			bias-pull-up = <MTK_PUPD_SET_R1R0_01>;
			output-high;
		};
	};

	dischg_disable: dischg_disable {
		pins_cmd_dat {
			pinmux = <PINMUX_GPIO51__FUNC_GPIO51>;		//check
			output-enable;
			bias-pull-down = <MTK_PUPD_SET_R1R0_01>;
			output-low;
		};
	};

	vooc_asic_id_active: vooc_asic_id_active {
		pins_cmd_dat {
			pinmux = <PINMUX_GPIO187__FUNC_GPIO187>;
			input-enable;
			slew-rate = <0>;
			bias-pull-up = <MTK_PUPD_SET_R1R0_10>;
		};
	};

	vooc_asic_id_sleep: vooc_asic_id_sleep {
		pins_cmd_dat {
			pinmux = <PINMUX_GPIO187__FUNC_GPIO187>;
			input-enable;
			slew-rate = <0>;
			bias-pull-down = <MTK_PUPD_SET_R1R0_10>;
		};
	};
	ccdetect_active: ccdetect_active {
		pins_cmd_dat {
			pinmux = <PINMUX_GPIO5__FUNC_GPIO5>;
			input-enable;
			slew-rate = <0>;
			bias-disable;
		};
	};
	ccdetect_sleep: ccdetect_sleep {
		pins_cmd_dat {
			pinmux = <PINMUX_GPIO5__FUNC_GPIO5>;
			input-enable;
			slew-rate = <0>;
			bias-disable;
		};
	};
	/*
	shortc_active_gpio: shortc_active {
		pins_cmd_dat {
			pinmux = <PINMUX_GPIO121__FUNC_GPIO121>;
			input-enable;
			slew-rate = <0>;
			bias-pull-up;
		};
	};*/

	//Lukaili Add for camera flash led
	chgvin_enable: chgvin_enable {
		pins_cmd_dat {
			pinmux = <PINMUX_GPIO30__FUNC_GPIO30>;				//check
			slew-rate = <1>;//0:input direction 1:output direction
			bias-pull-up;
			output-low;
		};
	};

	chgvin_disable: chgvin_disable {
		pins_cmd_dat {
			pinmux = <PINMUX_GPIO30__FUNC_GPIO30>;			//check
			slew-rate = <1>;
			bias-pull-down;
			output-high;
		};
	};
	pmic_chgfunc_enable: pmic_chgfunc_enable {
		pins_cmd_dat {
			pinmux = <PINMUX_GPIO26__FUNC_GPIO26>;			//check
			slew-rate = <1>;//0:input direction 1:output direction
			bias-pull-up;
			output-low;
		};
	};

	pmic_chgfunc_disable: pmic_chgfunc_disable {
		pins_cmd_dat {
			pinmux = <PINMUX_GPIO26__FUNC_GPIO26>;			//check
			slew-rate = <1>;
			bias-pull-down;
			output-high;
		};
	};
	mps_otg_en_active: mps_otg_en_active {
		pins_cmd_dat {
			pinmux = <PINMUX_GPIO129__FUNC_GPIO129>;		//check
			slew-rate = <1>;
			bias-pull-up;
		};
	};

	mps_otg_en_sleep: mps_otg_en_sleep {
		pins_cmd_dat {
			pinmux = <PINMUX_GPIO129__FUNC_GPIO129>;		//check
			slew-rate = <1>;
			bias-pull-down;
		};
	};

	mps_otg_en_default: mps_otg_en_default {
		pins_cmd_dat {
			pinmux = <PINMUX_GPIO129__FUNC_GPIO129>;		//check
			slew-rate = <1>;
			bias-pull-down;
		};
	};
	charge_pump_hwid_active: charge_pump_hwid_active {
		pins_cmd_dat {
			pinmux = <PINMUX_GPIO147__FUNC_GPIO147>;		//check
			input-enable;
			slew-rate = <0>;
			bias-pull-up;
		};
	};

	charge_pump_hwid_sleep: charge_pump_hwid_sleep {
		pins_cmd_dat {
			pinmux = <PINMUX_GPIO147__FUNC_GPIO147>;		//check
			input-enable;
			slew-rate = <0>;
			bias-pull-down;
		};
	};

	charge_pump_hwid_default: charge_pump_hwid_default {
		pins_cmd_dat {
			pinmux = <PINMUX_GPIO147__FUNC_GPIO147>;		//check
			input-enable;
			slew-rate = <0>;
			bias-disable;
		};
	};
	//end Add for camera flash led
};


&i2c7 {
	pinctrl-names = "i2c-state", "output-low-state","i2c-state-scl", "output-low-state-scl";
	pinctrl-0 = <&i2c7_i2c_state>;
	pinctrl-1 = <&i2c7_output_low_state>;
	pinctrl-2 = <&i2c7_i2c_state_scl>;
	pinctrl-3 = <&i2c7_output_low_state_scl>;
};
&pio {
	i2c7_i2c_state: i2c7_sda_i2c_state {
		pins_cmd_dat {
			pinmux = <PINMUX_GPIO125__FUNC_SDA7>;
			slew-rate = <0>;
			bias-disable;
		};
	};
	i2c7_output_low_state: i2c7_sda_output_low_state {
		pins_cmd_dat {
			pinmux = <PINMUX_GPIO125__FUNC_GPIO125>;
			slew-rate = <1>;
			output-low;
		};
	};
	i2c7_i2c_state_scl: i2c7_scl_i2c_state {
		pins_cmd_dat {
			pinmux = <PINMUX_GPIO124__FUNC_SCL7>;
			slew-rate = <0>;
			bias-disable;
		};
	};
	i2c7_output_low_state_scl: i2c7_scl_output_low_state {
		pins_cmd_dat {
			pinmux = <PINMUX_GPIO124__FUNC_GPIO124>;
			slew-rate = <1>;
			output-low;
		};
	};
};

&pio {
	charging_switch1_active: charging_switch1_active {
		pins_cmd_dat {
			pinmux = <PINMUX_GPIO191__FUNC_GPIO191>;		//check
			slew-rate = <1>;
			output-high;
		};
	};

	charging_switch1_sleep: charging_switch1_sleep {
		pins_cmd_dat {
			pinmux = <PINMUX_GPIO191__FUNC_GPIO191>;		//check
			slew-rate = <1>;
			output-low;
		};
	};

	charging_switch1_ctr1_active: charging_switch1_ctr1_active {
		pins_cmd_dat {
			pinmux = <PINMUX_GPIO163__FUNC_GPIO163>;		//empty
			slew-rate = <1>;
			bias-pull-up;
		};
	};
	charging_switch1_ctr1_sleep: charging_switch1_ctr1_sleep {
		pins_cmd_dat {
			pinmux = <PINMUX_GPIO163__FUNC_GPIO163>;		//empty
			slew-rate = <1>;
			output-low;
		};
	};

	charging_clock_active: charging_clock_active {
		pins_cmd_dat {
			pinmux = <PINMUX_GPIO95__FUNC_GPIO95>;		//check
			slew-rate = <0>;
			bias-pull-up;
		};
	};

	charging_clock_sleep: charging_clock_sleep {
		pins_cmd_dat {
			pinmux = <PINMUX_GPIO95__FUNC_GPIO95>;		//check
			slew-rate = <0>;
			bias-pull-down;
		};
	};

	charging_data_active: charging_data_active {
		pins_cmd_dat {
			pinmux = <PINMUX_GPIO94__FUNC_GPIO94>;		//check
			slew-rate = <0>;
			bias-pull-down;
		};
	};

	charging_data_sleep: charging_data_sleep {
		pins_cmd_dat {
			pinmux = <PINMUX_GPIO94__FUNC_GPIO94>;		//check
			slew-rate = <0>;
			bias-pull-down;
		};
	};

	charging_reset_active: charging_reset_active {
		pins_cmd_dat {
			pinmux = <PINMUX_GPIO189__FUNC_GPIO189>;	//check
			slew-rate = <1>;
			bias-pull-down;
		};
	};

	charging_reset_sleep: charging_reset_sleep {
		pins_cmd_dat {
			pinmux = <PINMUX_GPIO189__FUNC_GPIO189>;	//check
			slew-rate = <1>;
			bias-pull-up;
		};
	};


};
